VERSION ""

NS_ :

BS_:

BU_: AUDIOamp A_IVC CGW CentralPanel FCP IVI RCP RSE_L

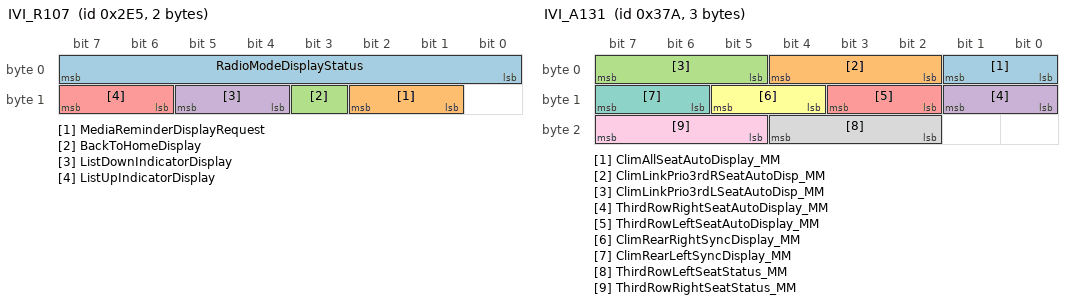
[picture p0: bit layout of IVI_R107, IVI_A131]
BO_ 741 IVI_R107: 2 IVI
  SG_ RadioModeDisplayStatus : 7|8@0+ (1,0) [0|254] "wu" CGW
  SG_ MediaReminderDisplayRequest : 10|2@0+ (1,0) [0|0] "" CGW
  SG_ BackToHomeDisplay : 11|1@0+ (1,0) [0|0] "" CGW
  SG_ ListDownIndicatorDisplay : 13|2@0+ (1,0) [0|0] "" CGW
  SG_ ListUpIndicatorDisplay : 15|2@0+ (1,0) [0|0] "" CGW

BO_ 890 IVI_A131: 3 IVI
  SG_ ClimAllSeatAutoDisplay_MM : 1|2@0+ (1,0) [0|0] "" FCP
  SG_ ClimLinkPrio3rdRSeatAutoDisp_MM : 4|3@0+ (1,0) [0|0] "" FCP
  SG_ ClimLinkPrio3rdLSeatAutoDisp_MM : 7|3@0+ (1,0) [0|0] "" FCP
  SG_ ThirdRowRightSeatAutoDisplay_MM : 9|2@0+ (1,0) [0|0] "" FCP,RCP
  SG_ ThirdRowLeftSeatAutoDisplay_MM : 11|2@0+ (1,0) [0|0] "" FCP,RCP
  SG_ ClimRearRightSyncDisplay_MM : 13|2@0+ (1,0) [0|0] "" FCP,RCP
  SG_ ClimRearLeftSyncDisplay_MM : 15|2@0+ (1,0) [0|0] "" FCP,RCP
  SG_ ThirdRowLeftSeatStatus_MM : 20|3@0+ (1,0) [0|0] "" FCP,RCP
  SG_ ThirdRowRightSeatStatus_MM : 23|3@0+ (1,0) [0|0] "" FCP,RCP

BO_ 920 OSP_Info: 8 IVI
  SG_ NavigationAlertDisplayRequest : 7|3@0+ (1,0) [0|0] "" CGW

BO_ 945 CentralPanel_R101: 2 CentralPanel
  SG_ CentralPanelMMSwitch : 6|3@0+ (1,0) [0|0] "" IVI
  SG_ CPdisplayAvailability : 7|1@0+ (1,0) [0|0] "" IVI

BO_ 961 IVI_A112: 8 IVI
  SG_ MMI_MultimediaState : 52|3@0+ (1,0) [0|0] "" CentralPanel

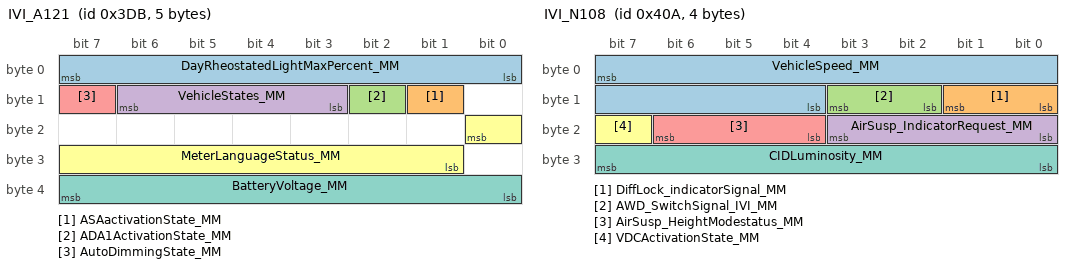
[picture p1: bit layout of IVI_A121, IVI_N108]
BO_ 987 IVI_A121: 5 IVI
  SG_ DayRheostatedLightMaxPercent_MM : 7|8@0+ (0.4,0) [0|100] "%" FCP
  SG_ ASAactivationState_MM : 9|1@0+ (1,0) [0|0] "" FCP
  SG_ ADA1ActivationState_MM : 10|1@0+ (1,0) [0|0] "" FCP
  SG_ VehicleStates_MM : 14|4@0+ (1,0) [0|0] "" CentralPanel,FCP
  SG_ AutoDimmingState_MM : 15|1@0+ (1,0) [0|0] "" CentralPanel
  SG_ MeterLanguageStatus_MM : 16|8@0+ (1,0) [0|0] "" FCP
  SG_ BatteryVoltage_MM : 39|8@0+ (0.06,6) [6|18] "V" FCP,RCP

BO_ 1026 UserSetPrefs2_MM_HS: 2 IVI
  SG_ CPdisplayDayLuminosityRequest : 6|5@0+ (5,0) [0|100] "%" CentralPanel
  SG_ CPdisplayNightLuminosityRequest : 12|5@0+ (5,0) [0|100] "%" CentralPanel

BO_ 1034 IVI_N108: 4 IVI
  SG_ VehicleSpeed_MM : 7|12@0+ (0.1,0) [0|300] "km/h" FCP
  SG_ DiffLock_indicatorSignal_MM : 9|2@0+ (1,0) [0|0] "" FCP
  SG_ AWD_SwitchSignal_IVI_MM : 11|2@0+ (1,0) [0|0] "" FCP
  SG_ AirSusp_IndicatorRequest_MM : 19|4@0+ (1,0) [0|0] "" FCP
  SG_ AirSusp_HeightModestatus_MM : 22|3@0+ (1,0) [0|0] "" FCP
  SG_ VDCActivationState_MM : 23|1@0+ (1,0) [0|0] "" FCP
  SG_ CIDLuminosity_MM : 31|8@0+ (0.4,0) [0|100] "%" CGW

BO_ 1067 HEVC_A107: 8 CGW
  SG_ RE_ElecMachineSpeed_BLMS : 42|12@0+ (10,-20000) [-20000|20000] "rpm" AUDIOamp,IVI

BO_ 1087 FCP_N101: 1 FCP
  SG_ AirSUSP_ControlPanelRequest_FCP : 2|2@0+ (1,0) [0|0] "" IVI

BO_ 1135 IVI_R104: 4 IVI
  SG_ AutoDimmingOffsetY0_MM : 7|4@0+ (1,0) [0|0] "" CentralPanel

BO_ 1158 IVI_A16: 3 IVI
  SG_ DayNightStatusForB_Switches_MM : 6|1@0+ (1,0) [0|0] "" CentralPanel
  SG_ ProbableCustomerFeedBackNeed_MM : 22|1@0+ (1,0) [0|0] "" CentralPanel

BO_ 1217 METER_A115: 8 CGW
  SG_ Uniform_Symbol_099_displayed : 1|2@0+ (1,0) [0|0] "" IVI
  SG_ Uniform_Symbol_098_displayed : 3|2@0+ (1,0) [0|0] "" IVI
  SG_ Uniform_Symbol_097_displayed : 5|2@0+ (1,0) [0|0] "" IVI
  SG_ Uniform_Symbol_096_displayed : 7|2@0+ (1,0) [0|0] "" IVI
  SG_ Uniform_Symbol_103_displayed : 9|2@0+ (1,0) [0|0] "" IVI
  SG_ Uniform_Symbol_102_displayed : 11|2@0+ (1,0) [0|0] "" IVI
  SG_ Uniform_Symbol_101_displayed : 13|2@0+ (1,0) [0|0] "" IVI
  SG_ Uniform_Symbol_100_displayed : 15|2@0+ (1,0) [0|0] "" IVI
  SG_ Uniform_Symbol_107_displayed : 17|2@0+ (1,0) [0|0] "" IVI
  SG_ Uniform_Symbol_106_displayed : 19|2@0+ (1,0) [0|0] "" IVI
  SG_ Uniform_Symbol_105_displayed : 21|2@0+ (1,0) [0|0] "" IVI
  SG_ Uniform_Symbol_104_displayed : 23|2@0+ (1,0) [0|0] "" IVI
  SG_ Uniform_Symbol_111_displayed : 25|2@0+ (1,0) [0|0] "" IVI
  SG_ Uniform_Symbol_110_displayed : 27|2@0+ (1,0) [0|0] "" IVI
  SG_ Uniform_Symbol_109_displayed : 29|2@0+ (1,0) [0|0] "" IVI
  SG_ Uniform_Symbol_108_displayed : 31|2@0+ (1,0) [0|0] "" IVI
  SG_ Uniform_Symbol_115_displayed : 33|2@0+ (1,0) [0|0] "" IVI
  SG_ Uniform_Symbol_114_displayed : 35|2@0+ (1,0) [0|0] "" IVI
  SG_ Uniform_Symbol_113_displayed : 37|2@0+ (1,0) [0|0] "" IVI
  SG_ Uniform_Symbol_112_displayed : 39|2@0+ (1,0) [0|0] "" IVI
  SG_ Uniform_Symbol_119_displayed : 41|2@0+ (1,0) [0|0] "" IVI
  SG_ Uniform_Symbol_118_displayed : 43|2@0+ (1,0) [0|0] "" IVI
  SG_ Uniform_Symbol_117_displayed : 45|2@0+ (1,0) [0|0] "" IVI
  SG_ Uniform_Symbol_116_displayed : 47|2@0+ (1,0) [0|0] "" IVI
  SG_ Uniform_Symbol_123_displayed : 49|2@0+ (1,0) [0|0] "" IVI
  SG_ Uniform_Symbol_122_displayed : 51|2@0+ (1,0) [0|0] "" IVI
  SG_ Uniform_Symbol_121_displayed : 53|2@0+ (1,0) [0|0] "" IVI
  SG_ Uniform_Symbol_120_displayed : 55|2@0+ (1,0) [0|0] "" IVI
  SG_ Uniform_Symbol_127_displayed : 57|2@0+ (1,0) [0|0] "" IVI
  SG_ Uniform_Symbol_126_displayed : 59|2@0+ (1,0) [0|0] "" IVI
  SG_ Uniform_Symbol_125_displayed : 61|2@0+ (1,0) [0|0] "" IVI
  SG_ Uniform_Symbol_124_displayed : 63|2@0+ (1,0) [0|0] "" IVI

BO_ 1222 METER_A116: 8 CGW
  SG_ Uniform_Symbol_131_displayed : 1|2@0+ (1,0) [0|0] "" IVI
  SG_ Uniform_Symbol_130_displayed : 3|2@0+ (1,0) [0|0] "" IVI
  SG_ Uniform_Symbol_129_displayed : 5|2@0+ (1,0) [0|0] "" IVI
  SG_ Uniform_Symbol_128_displayed : 7|2@0+ (1,0) [0|0] "" IVI
  SG_ Uniform_Symbol_135_displayed : 9|2@0+ (1,0) [0|0] "" IVI
  SG_ Uniform_Symbol_134_displayed : 11|2@0+ (1,0) [0|0] "" IVI
  SG_ Uniform_Symbol_133_displayed : 13|2@0+ (1,0) [0|0] "" IVI
  SG_ Uniform_Symbol_132_displayed : 15|2@0+ (1,0) [0|0] "" IVI
  SG_ Uniform_Symbol_139_displayed : 17|2@0+ (1,0) [0|0] "" IVI
  SG_ Uniform_Symbol_138_displayed : 19|2@0+ (1,0) [0|0] "" IVI
  SG_ Uniform_Symbol_137_displayed : 21|2@0+ (1,0) [0|0] "" IVI
  SG_ Uniform_Symbol_136_displayed : 23|2@0+ (1,0) [0|0] "" IVI
  SG_ Uniform_Symbol_143_displayed : 25|2@0+ (1,0) [0|0] "" IVI
  SG_ Uniform_Symbol_142_displayed : 27|2@0+ (1,0) [0|0] "" IVI
  SG_ Uniform_Symbol_141_displayed : 29|2@0+ (1,0) [0|0] "" IVI
  SG_ Uniform_Symbol_140_displayed : 31|2@0+ (1,0) [0|0] "" IVI
  SG_ Uniform_Symbol_147_displayed : 33|2@0+ (1,0) [0|0] "" IVI
  SG_ Uniform_Symbol_146_displayed : 35|2@0+ (1,0) [0|0] "" IVI
  SG_ Uniform_Symbol_145_displayed : 37|2@0+ (1,0) [0|0] "" IVI
  SG_ Uniform_Symbol_144_displayed : 39|2@0+ (1,0) [0|0] "" IVI
  SG_ Uniform_Symbol_151_displayed : 41|2@0+ (1,0) [0|0] "" IVI
  SG_ Uniform_Symbol_150_displayed : 43|2@0+ (1,0) [0|0] "" IVI
  SG_ Uniform_Symbol_149_displayed : 45|2@0+ (1,0) [0|0] "" IVI
  SG_ Uniform_Symbol_148_displayed : 47|2@0+ (1,0) [0|0] "" IVI
  SG_ Uniform_Symbol_155_displayed : 49|2@0+ (1,0) [0|0] "" IVI
  SG_ Uniform_Symbol_154_displayed : 51|2@0+ (1,0) [0|0] "" IVI
  SG_ Uniform_Symbol_153_displayed : 53|2@0+ (1,0) [0|0] "" IVI
  SG_ Uniform_Symbol_152_displayed : 55|2@0+ (1,0) [0|0] "" IVI
  SG_ Uniform_Symbol_159_displayed : 57|2@0+ (1,0) [0|0] "" IVI
  SG_ Uniform_Symbol_158_displayed : 59|2@0+ (1,0) [0|0] "" IVI
  SG_ Uniform_Symbol_157_displayed : 61|2@0+ (1,0) [0|0] "" IVI
  SG_ Uniform_Symbol_156_displayed : 63|2@0+ (1,0) [0|0] "" IVI

BO_ 1229 METER_A117: 8 CGW
  SG_ Uniform_Symbol_163_displayed : 1|2@0+ (1,0) [0|0] "" IVI
  SG_ Uniform_Symbol_162_displayed : 3|2@0+ (1,0) [0|0] "" IVI
  SG_ Uniform_Symbol_161_displayed : 5|2@0+ (1,0) [0|0] "" IVI
  SG_ Uniform_Symbol_160_displayed : 7|2@0+ (1,0) [0|0] "" IVI
  SG_ Uniform_Symbol_167_displayed : 9|2@0+ (1,0) [0|0] "" IVI
  SG_ Uniform_Symbol_166_displayed : 11|2@0+ (1,0) [0|0] "" IVI
  SG_ Uniform_Symbol_165_displayed : 13|2@0+ (1,0) [0|0] "" IVI
  SG_ Uniform_Symbol_164_displayed : 15|2@0+ (1,0) [0|0] "" IVI
  SG_ Uniform_Symbol_171_displayed : 17|2@0+ (1,0) [0|0] "" IVI
  SG_ Uniform_Symbol_170_displayed : 19|2@0+ (1,0) [0|0] "" IVI
  SG_ Uniform_Symbol_169_displayed : 21|2@0+ (1,0) [0|0] "" IVI
  SG_ Uniform_Symbol_168_displayed : 23|2@0+ (1,0) [0|0] "" IVI
  SG_ Uniform_Symbol_175_displayed : 25|2@0+ (1,0) [0|0] "" IVI
  SG_ Uniform_Symbol_174_displayed : 27|2@0+ (1,0) [0|0] "" IVI
  SG_ Uniform_Symbol_173_displayed : 29|2@0+ (1,0) [0|0] "" IVI
  SG_ Uniform_Symbol_172_displayed : 31|2@0+ (1,0) [0|0] "" IVI
  SG_ Uniform_Symbol_179_displayed : 33|2@0+ (1,0) [0|0] "" IVI
  SG_ Uniform_Symbol_178_displayed : 35|2@0+ (1,0) [0|0] "" IVI
  SG_ Uniform_Symbol_177_displayed : 37|2@0+ (1,0) [0|0] "" IVI
  SG_ Uniform_Symbol_176_displayed : 39|2@0+ (1,0) [0|0] "" IVI
  SG_ Uniform_Symbol_183_displayed : 41|2@0+ (1,0) [0|0] "" IVI
  SG_ Uniform_Symbol_182_displayed : 43|2@0+ (1,0) [0|0] "" IVI
  SG_ Uniform_Symbol_181_displayed : 45|2@0+ (1,0) [0|0] "" IVI
  SG_ Uniform_Symbol_180_displayed : 47|2@0+ (1,0) [0|0] "" IVI
  SG_ Uniform_Symbol_187_displayed : 49|2@0+ (1,0) [0|0] "" IVI
  SG_ Uniform_Symbol_186_displayed : 51|2@0+ (1,0) [0|0] "" IVI
  SG_ Uniform_Symbol_185_displayed : 53|2@0+ (1,0) [0|0] "" IVI
  SG_ Uniform_Symbol_184_displayed : 55|2@0+ (1,0) [0|0] "" IVI
  SG_ Uniform_Symbol_191_displayed : 57|2@0+ (1,0) [0|0] "" IVI
  SG_ Uniform_Symbol_190_displayed : 59|2@0+ (1,0) [0|0] "" IVI
  SG_ Uniform_Symbol_189_displayed : 61|2@0+ (1,0) [0|0] "" IVI
  SG_ Uniform_Symbol_188_displayed : 63|2@0+ (1,0) [0|0] "" IVI

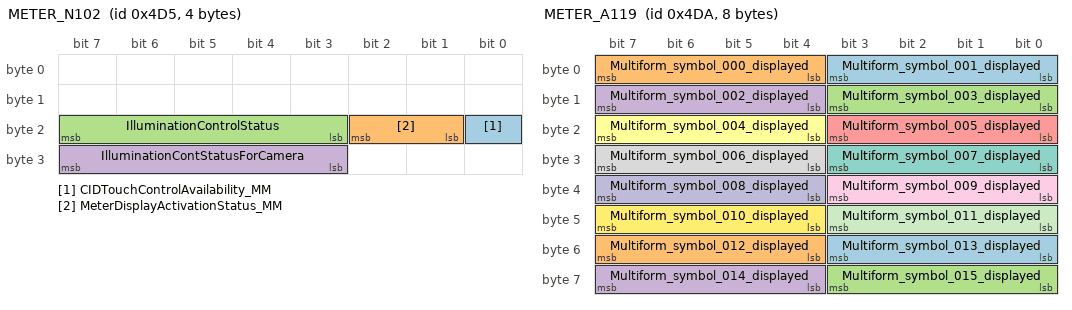
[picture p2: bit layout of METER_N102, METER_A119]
BO_ 1237 METER_N102: 4 CGW
  SG_ CIDTouchControlAvailability_MM : 16|1@0+ (1,0) [0|0] "" IVI
  SG_ MeterDisplayActivationStatus_MM : 18|2@0+ (1,0) [0|0] "" IVI
  SG_ IlluminationControlStatus : 23|5@0+ (1,0) [0|0] "" IVI
  SG_ IlluminationContStatusForCamera : 31|5@0+ (1,0) [0|0] "" IVI

BO_ 1238 METER_A118: 8 CGW
  SG_ Uniform_Symbol_195_displayed : 1|2@0+ (1,0) [0|0] "" IVI
  SG_ Uniform_Symbol_194_displayed : 3|2@0+ (1,0) [0|0] "" IVI
  SG_ Uniform_Symbol_193_displayed : 5|2@0+ (1,0) [0|0] "" IVI
  SG_ Uniform_Symbol_192_displayed : 7|2@0+ (1,0) [0|0] "" IVI
  SG_ Uniform_Symbol_199_displayed : 9|2@0+ (1,0) [0|0] "" IVI
  SG_ Uniform_Symbol_198_displayed : 11|2@0+ (1,0) [0|0] "" IVI
  SG_ Uniform_Symbol_197_displayed : 13|2@0+ (1,0) [0|0] "" IVI
  SG_ Uniform_Symbol_196_displayed : 15|2@0+ (1,0) [0|0] "" IVI
  SG_ Uniform_Symbol_203_displayed : 17|2@0+ (1,0) [0|0] "" IVI
  SG_ Uniform_Symbol_202_displayed : 19|2@0+ (1,0) [0|0] "" IVI
  SG_ Uniform_Symbol_201_displayed : 21|2@0+ (1,0) [0|0] "" IVI
  SG_ Uniform_Symbol_200_displayed : 23|2@0+ (1,0) [0|0] "" IVI
  SG_ Uniform_Symbol_207_displayed : 25|2@0+ (1,0) [0|0] "" IVI
  SG_ Uniform_Symbol_206_displayed : 27|2@0+ (1,0) [0|0] "" IVI
  SG_ Uniform_Symbol_205_displayed : 29|2@0+ (1,0) [0|0] "" IVI
  SG_ Uniform_Symbol_204_displayed : 31|2@0+ (1,0) [0|0] "" IVI
  SG_ Uniform_Symbol_211_displayed : 33|2@0+ (1,0) [0|0] "" IVI
  SG_ Uniform_Symbol_210_displayed : 35|2@0+ (1,0) [0|0] "" IVI
  SG_ Uniform_Symbol_209_displayed : 37|2@0+ (1,0) [0|0] "" IVI
  SG_ Uniform_Symbol_208_displayed : 39|2@0+ (1,0) [0|0] "" IVI
  SG_ Uniform_Symbol_215_displayed : 41|2@0+ (1,0) [0|0] "" IVI
  SG_ Uniform_Symbol_214_displayed : 43|2@0+ (1,0) [0|0] "" IVI
  SG_ Uniform_Symbol_213_displayed : 45|2@0+ (1,0) [0|0] "" IVI
  SG_ Uniform_Symbol_212_displayed : 47|2@0+ (1,0) [0|0] "" IVI
  SG_ Uniform_Symbol_219_displayed : 49|2@0+ (1,0) [0|0] "" IVI
  SG_ Uniform_Symbol_218_displayed : 51|2@0+ (1,0) [0|0] "" IVI
  SG_ Uniform_Symbol_217_displayed : 53|2@0+ (1,0) [0|0] "" IVI
  SG_ Uniform_Symbol_216_displayed : 55|2@0+ (1,0) [0|0] "" IVI
  SG_ Uniform_Symbol_223_displayed : 57|2@0+ (1,0) [0|0] "" IVI
  SG_ Uniform_Symbol_222_displayed : 59|2@0+ (1,0) [0|0] "" IVI
  SG_ Uniform_Symbol_221_displayed : 61|2@0+ (1,0) [0|0] "" IVI
  SG_ Uniform_Symbol_220_displayed : 63|2@0+ (1,0) [0|0] "" IVI

BO_ 1242 METER_A119: 8 CGW
  SG_ Multiform_symbol_001_displayed : 3|4@0+ (1,0) [0|0] "" IVI
  SG_ Multiform_symbol_000_displayed : 7|4@0+ (1,0) [0|0] "" IVI
  SG_ Multiform_symbol_003_displayed : 11|4@0+ (1,0) [0|0] "" IVI
  SG_ Multiform_symbol_002_displayed : 15|4@0+ (1,0) [0|0] "" IVI
  SG_ Multiform_symbol_005_displayed : 19|4@0+ (1,0) [0|0] "" IVI
  SG_ Multiform_symbol_004_displayed : 23|4@0+ (1,0) [0|0] "" IVI
  SG_ Multiform_symbol_007_displayed : 27|4@0+ (1,0) [0|0] "" IVI
  SG_ Multiform_symbol_006_displayed : 31|4@0+ (1,0) [0|0] "" IVI
  SG_ Multiform_symbol_009_displayed : 35|4@0+ (1,0) [0|0] "" IVI
  SG_ Multiform_symbol_008_displayed : 39|4@0+ (1,0) [0|0] "" IVI
  SG_ Multiform_symbol_011_displayed : 43|4@0+ (1,0) [0|0] "" IVI
  SG_ Multiform_symbol_010_displayed : 47|4@0+ (1,0) [0|0] "" IVI
  SG_ Multiform_symbol_013_displayed : 51|4@0+ (1,0) [0|0] "" IVI
  SG_ Multiform_symbol_012_displayed : 55|4@0+ (1,0) [0|0] "" IVI
  SG_ Multiform_symbol_015_displayed : 59|4@0+ (1,0) [0|0] "" IVI
  SG_ Multiform_symbol_014_displayed : 63|4@0+ (1,0) [0|0] "" IVI

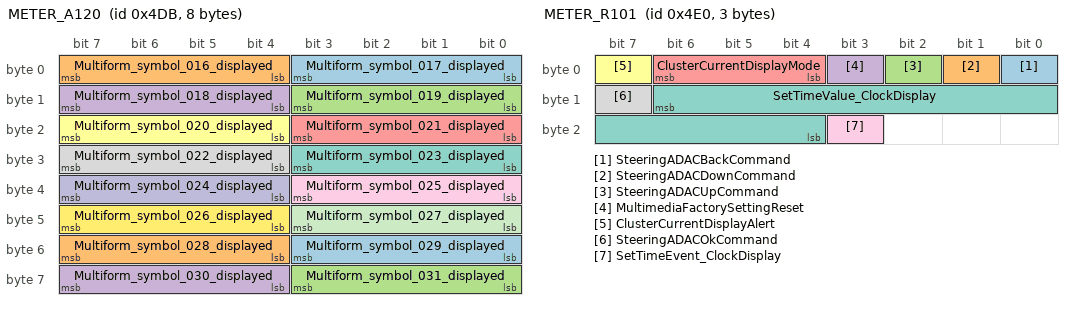
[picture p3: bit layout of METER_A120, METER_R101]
BO_ 1243 METER_A120: 8 CGW
  SG_ Multiform_symbol_017_displayed : 3|4@0+ (1,0) [0|0] "" IVI
  SG_ Multiform_symbol_016_displayed : 7|4@0+ (1,0) [0|0] "" IVI
  SG_ Multiform_symbol_019_displayed : 11|4@0+ (1,0) [0|0] "" IVI
  SG_ Multiform_symbol_018_displayed : 15|4@0+ (1,0) [0|0] "" IVI
  SG_ Multiform_symbol_021_displayed : 19|4@0+ (1,0) [0|0] "" IVI
  SG_ Multiform_symbol_020_displayed : 23|4@0+ (1,0) [0|0] "" IVI
  SG_ Multiform_symbol_023_displayed : 27|4@0+ (1,0) [0|0] "" IVI
  SG_ Multiform_symbol_022_displayed : 31|4@0+ (1,0) [0|0] "" IVI
  SG_ Multiform_symbol_025_displayed : 35|4@0+ (1,0) [0|0] "" IVI
  SG_ Multiform_symbol_024_displayed : 39|4@0+ (1,0) [0|0] "" IVI
  SG_ Multiform_symbol_027_displayed : 43|4@0+ (1,0) [0|0] "" IVI
  SG_ Multiform_symbol_026_displayed : 47|4@0+ (1,0) [0|0] "" IVI
  SG_ Multiform_symbol_029_displayed : 51|4@0+ (1,0) [0|0] "" IVI
  SG_ Multiform_symbol_028_displayed : 55|4@0+ (1,0) [0|0] "" IVI
  SG_ Multiform_symbol_031_displayed : 59|4@0+ (1,0) [0|0] "" IVI
  SG_ Multiform_symbol_030_displayed : 63|4@0+ (1,0) [0|0] "" IVI

BO_ 1248 METER_R101: 3 CGW
  SG_ SteeringADACBackCommand : 0|1@0+ (1,0) [0|0] "" IVI
  SG_ SteeringADACDownCommand : 1|1@0+ (1,0) [0|0] "" IVI
  SG_ SteeringADACUpCommand : 2|1@0+ (1,0) [0|0] "" IVI
  SG_ MultimediaFactorySettingReset : 3|1@0+ (1,0) [0|0] "" IVI
  SG_ ClusterCurrentDisplayMode : 6|3@0+ (1,0) [0|0] "" IVI
  SG_ ClusterCurrentDisplayAlert : 7|1@0+ (1,0) [0|0] "" IVI
  SG_ SetTimeValue_ClockDisplay : 14|11@0+ (1,0) [0|1440] "min" IVI
  SG_ SteeringADACOkCommand : 15|1@0+ (1,0) [0|0] "" IVI
  SG_ SetTimeEvent_ClockDisplay : 19|1@0+ (1,0) [0|0] "" IVI

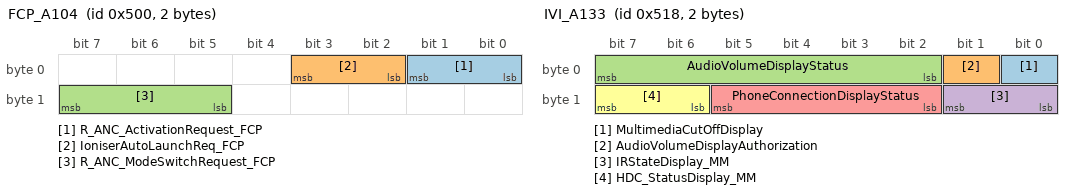
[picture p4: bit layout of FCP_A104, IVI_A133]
BO_ 1280 FCP_A104: 2 FCP
  SG_ R_ANC_ActivationRequest_FCP : 1|2@0+ (1,0) [0|0] "" IVI
  SG_ IoniserAutoLaunchReq_FCP : 3|2@0+ (1,0) [0|0] "" IVI
  SG_ R_ANC_ModeSwitchRequest_FCP : 15|3@0+ (1,0) [0|0] "" IVI

BO_ 1283 RCP_A102: 7 RCP
  SG_ RRLeftMassageActivationReq_RCP : 1|2@0+ (1,0) [0|0] "" IVI
  SG_ RRLeftLumbarMovingReq_Z_Axis_RCP : 3|2@0+ (1,0) [0|0] "" IVI
  SG_ RRLeftLumbarMovingReq_X_Axis_RCP : 5|2@0+ (1,0) [0|0] "" IVI
  SG_ RRLeftFrontHeightMovingReq_RCP : 7|2@0+ (1,0) [0|0] "" IVI
  SG_ RRLeftOttomanMovingReq_RCP : 9|2@0+ (1,0) [0|0] "" IVI
  SG_ RRLeftMassageVelocityReq_RCP : 12|3@0+ (1,0) [0|0] "" IVI
  SG_ RRLeftMassageIntensityReq_RCP : 15|3@0+ (1,0) [0|0] "" IVI
  SG_ RRLeftSlideMovingReq_RCP : 17|2@0+ (1,0) [0|0] "" IVI
  SG_ RRLeftReclinerMovingReq_RCP : 19|2@0+ (1,0) [0|0] "" IVI
  SG_ RRLeftMassageProgramReq_RCP : 23|4@0+ (1,0) [0|0] "" IVI
  SG_ RRLeftUpperbackrestMovingReq_RCP : 25|2@0+ (1,0) [0|0] "" IVI
  SG_ RRRightMassageIntensityReq_RCP : 28|3@0+ (1,0) [0|0] "" IVI
  SG_ RRRightMassageVelocityReq_RCP : 31|3@0+ (1,0) [0|0] "" IVI
  SG_ RRRightMassageActivationReq_RCP : 33|2@0+ (1,0) [0|0] "" IVI
  SG_ RRRightLumbarMovReq_Z_Axis_RCP : 35|2@0+ (1,0) [0|0] "" IVI
  SG_ RRRightLumbarMovReq_X_Axis_RCP : 37|2@0+ (1,0) [0|0] "" IVI
  SG_ RRRightFrontHeightMovingReq_RCP : 39|2@0+ (1,0) [0|0] "" IVI
  SG_ RRRightReclinerMovingReq_RCP : 41|2@0+ (1,0) [0|0] "" IVI
  SG_ RRRightOttomanMovingReq_RCP : 43|2@0+ (1,0) [0|0] "" IVI
  SG_ RRRightMassageProgramReq_RCP : 47|4@0+ (1,0) [0|0] "" IVI
  SG_ RearRightAutoReturnReq_RCP : 49|2@0+ (1,0) [0|0] "" IVI
  SG_ RearLeftAutoReturnReq_RCP : 51|2@0+ (1,0) [0|0] "" IVI
  SG_ RRRightUpperbackrestMovReq_RCP : 53|2@0+ (1,0) [0|0] "" IVI
  SG_ RRRightSlideMovingReq_RCP : 55|2@0+ (1,0) [0|0] "" IVI

BO_ 1287 IVI_A125: 8 IVI
  SG_ ClimRightTempDisplay_MM : 7|8@0+ (0.5,0) [10|127.5] "°" FCP
  SG_ ClimTempDisplay_MM : 15|8@0+ (0.5,0) [10|127.5] "°" FCP
  SG_ ClimFlowDistrDisplay_MM : 19|4@0+ (1,0) [0|0] "" FCP
  SG_ ClimBlowerLevelDisplay_MM : 23|4@0+ (1,0) [0|0] "" FCP
  SG_ ClimLinkMaxFanSpeedAutoDisp_MM : 24|3@0+ (1,0) [0|0] "" FCP
  SG_ ClimHumidSensorSensitivDisp_MM : 27|3@0+ (1,0) [0|0] "" FCP
  SG_ ClimLastFuncModiByCustomer_v2_MM : 31|4@0+ (1,0) [0|0] "" FCP
  SG_ ClimAutoDisplay_MM : 32|2@0+ (1,0) [0|0] "" FCP
  SG_ ClimACDisplay_MM : 34|2@0+ (1,0) [0|0] "" FCP
  SG_ ClimRightFlowDistrDisplay_MM : 37|3@0+ (1,0) [0|0] "" FCP
  SG_ ClimRightAutoDisplay_MM : 40|2@0+ (1,0) [0|0] "" FCP
  SG_ ClimForestDisplay_MM : 42|2@0+ (1,0) [0|0] "" FCP
  SG_ ClimDriverZoneDisplay_MM : 44|2@0+ (1,0) [0|0] "" FCP
  SG_ ClimClearnessDisplay_MM : 46|2@0+ (1,0) [0|0] "" FCP
  SG_ ClimClearnessDisplayStatus_MM : 49|1@0+ (1,0) [0|0] "" FCP
  SG_ ClimCabinTempDisplayUnit_MM : 50|1@0+ (1,0) [0|0] "" FCP,RCP
  SG_ ClimBlowingLevelDisplayStatus_MM : 51|1@0+ (1,0) [0|0] "" FCP,RCP
  SG_ ClimACDisplayStatus_MM : 52|1@0+ (1,0) [0|0] "" FCP
  SG_ ClimSyncDisplay_MM : 54|2@0+ (1,0) [0|0] "" FCP,RCP
  SG_ ClimSyncDisplayStatus_MM : 56|1@0+ (1,0) [0|0] "" FCP,RCP
  SG_ ClimRightTempDisplayStatus_MM : 57|1@0+ (1,0) [0|0] "" FCP
  SG_ ClimRightFloDistDisplayStatus_MM : 58|1@0+ (1,0) [0|0] "" FCP
  SG_ ClimOFFModeDisplayStatus_MM : 59|1@0+ (1,0) [0|0] "" FCP,RCP
  SG_ ClimOFFModeDisplay_MM : 60|1@0+ (1,0) [0|0] "" FCP
  SG_ ClimForestDisplayStatus_MM : 61|1@0+ (1,0) [0|0] "" FCP
  SG_ ClimFlowDistrDisplayStatus_MM : 62|1@0+ (1,0) [0|0] "" FCP,RCP
  SG_ ClimDriverZoneDisplayStatus_MM : 63|1@0+ (1,0) [0|0] "" FCP

BO_ 1288 IVI_A126: 8 IVI
  SG_ ClimRearLeftTempDisplay_MM : 7|8@0+ (0.5,10) [10|127.5] "°" FCP,RCP
  SG_ ClimRearRightTempDisplay_MM : 15|8@0+ (0.5,0) [10|127.5] "°" FCP,RCP
  SG_ ClimRearRightBlowLevelDisplay_MM : 19|4@0+ (1,0) [0|0] "" FCP,RCP
  SG_ ClimRearLeftBlowLevelDisplay_MM : 23|4@0+ (1,0) [0|0] "" FCP,RCP
  SG_ ClimRearLeftFlowDistrDisplay_MM : 25|3@0+ (1,0) [0|0] "" FCP,RCP
  SG_ ClimLinkPriorHeatStrgAutoDisp_MM : 28|3@0+ (1,0) [0|0] "" FCP
  SG_ ClimLinkPrioRearSeatsAutoDisp_MM : 31|3@0+ (1,0) [0|0] "" FCP
  SG_ SecondRowLeftSeatStatus_MM : 32|3@0+ (1,0) [0|0] "" FCP,RCP
  SG_ ClimVariableAirFlowDisplay_MM : 35|3@0+ (1,0) [0|0] "" FCP
  SG_ ClimRearRightFlowDistrDisplay_MM : 38|3@0+ (1,0) [0|0] "" FCP,RCP
  SG_ ClimRearLockStatus_MM : 40|2@0+ (1,0) [0|0] "" FCP,RCP
  SG_ ClimRearLeftAutoDisplay_MM : 42|2@0+ (1,0) [0|0] "" FCP,RCP
  SG_ SecondRowRightSeatStatus_MM : 45|3@0+ (1,0) [0|0] "" FCP,RCP
  SG_ ClimHeatedSteerWheelDispStatu_MM : 48|1@0+ (1,0) [0|0] "" FCP
  SG_ RearSeatsLockStatus_MM : 50|2@0+ (1,0) [0|0] "" FCP
  SG_ SecondRowRightSeatAutoDisplay_MM : 52|2@0+ (1,0) [0|0] "" FCP,RCP
  SG_ SecondRowLeftSeatAutoDisplay_MM : 54|2@0+ (1,0) [0|0] "" FCP,RCP
  SG_ SecondRowRightSeatDispStatus_MM : 56|1@0+ (1,0) [0|0] "" FCP,RCP
  SG_ SecondRowLeftSeatDispStatus_MM : 57|1@0+ (1,0) [0|0] "" FCP,RCP
  SG_ ClimTempDisplayStatus_MM : 58|1@0+ (1,0) [0|0] "" FCP
  SG_ ClimRearRightTempDispStatus_MM : 59|1@0+ (1,0) [0|0] "" FCP,RCP
  SG_ ClimRearRightFloDistDispStatu_MM : 60|1@0+ (1,0) [0|0] "" FCP,RCP
  SG_ ClimRearOFFModeDisplay_MM : 61|1@0+ (1,0) [0|0] "" FCP,RCP
  SG_ ClimRearLeftTempDisplayStatus_MM : 62|1@0+ (1,0) [0|0] "" FCP,RCP
  SG_ ClimRearLeftFlowDistDispStatu_MM : 63|1@0+ (1,0) [0|0] "" FCP,RCP

BO_ 1289 IVI_A127: 8 IVI
  SG_ RRRightMassageProgramState_MM : 3|4@0+ (1,0) [0|0] "" RCP
  SG_ RRLeftMassageProgramState_MM : 7|4@0+ (1,0) [0|0] "" RCP
  SG_ ClimLinkPrioritFLSeatAutoDisp_MM : 9|3@0+ (1,0) [0|0] "" FCP
  SG_ ClimAQSSensitivityDisplay_MM : 15|3@0+ (1,0) [0|0] "" FCP
  SG_ RRLeftMassageIntensityState_MM : 16|3@0+ (1,0) [0|0] "" RCP
  SG_ FrontRightSeatStatus_MM : 19|3@0+ (1,0) [0|0] "" FCP
  SG_ FrontLeftSeatStatus_MM : 22|3@0+ (1,0) [0|0] "" FCP
  SG_ RRLeftMassageVelocityState_MM : 26|3@0+ (1,0) [0|0] "" RCP
  SG_ RRRightMassageIntensityState_MM : 29|3@0+ (1,0) [0|0] "" RCP
  SG_ ClimForcedRecyDisplay_MM : 32|2@0+ (1,0) [0|0] "" FCP
  SG_ ClimForcedFreshDisplay_MM : 34|2@0+ (1,0) [0|0] "" FCP
  SG_ ClimAutoRecyclingDisplay_MM : 36|2@0+ (1,0) [0|0] "" FCP
  SG_ RRRightMassageVelocityState_MM : 39|3@0+ (1,0) [0|0] "" RCP
  SG_ FrontRightSeatAutoDisplay_MM : 40|2@0+ (1,0) [0|0] "" FCP
  SG_ FrontLeftSeatAutoDisplay_MM : 42|2@0+ (1,0) [0|0] "" FCP
  SG_ ClimRearDefrostDisplay_MM : 44|2@0+ (1,0) [0|0] "" FCP
  SG_ ClimFrontDefrostDisplay_MM : 46|2@0+ (1,0) [0|0] "" FCP
  SG_ ClimRearDefrostDisplayStatus_MM : 48|1@0+ (1,0) [0|0] "" FCP
  SG_ ClimFrontDefrostDisplayStatus_MM : 49|1@0+ (1,0) [0|0] "" FCP
  SG_ ClimForcedRecyDisplayStatus_MM : 50|1@0+ (1,0) [0|0] "" FCP
  SG_ ClimForcedFreshDisplayStatus_MM : 51|1@0+ (1,0) [0|0] "" FCP
  SG_ ClimAutoRecyDisplayStatus_MM : 52|1@0+ (1,0) [0|0] "" FCP
  SG_ IoniserAutoLaunchState_MM : 54|2@0+ (1,0) [0|0] "" FCP
  SG_ FrontRightSeatDisplayStatus_MM : 62|1@0+ (1,0) [0|0] "" FCP
  SG_ FrontLeftSeatDisplayStatus_MM : 63|1@0+ (1,0) [0|0] "" FCP

BO_ 1297 IVI_A128: 8 IVI
  SG_ PowerTrainSettingState_MM : 2|4@0+ (1,0) [0|0] "" FCP
  SG_ DriveModeState_MM : 7|5@0+ (1,0) [0|0] "" FCP
  SG_ VDCSettingState_MM : 10|4@0+ (1,0) [0|0] "" FCP
  SG_ SteeringSettingState_MM : 14|4@0+ (1,0) [0|0] "" FCP
  SG_ R_ANC_ModeStatus_MM : 16|3@0+ (1,0) [0|0] "" FCP
  SG_ CurrentUserState_v2_MM : 19|3@0+ (1,0) [0|0] "" FCP
  SG_ AWDSettingState_MM : 22|3@0+ (1,0) [0|0] "" FCP
  SG_ UserSettingCopySource_MM : 26|3@0+ (1,0) [0|0] "" FCP
  SG_ SuspensionSettingState_MM : 29|3@0+ (1,0) [0|0] "" FCP
  SG_ RRsunshadeRequest_MM : 32|2@0+ (1,0) [0|0] "" RCP
  SG_ R_ANC_ActivationStatus_MM : 34|2@0+ (1,0) [0|0] "" FCP
  SG_ ClimHeatedSteeringWheelDisp_MM : 36|2@0+ (1,0) [0|0] "" FCP
  SG_ UserSettingCopyTarget_MM : 39|3@0+ (1,0) [0|0] "" FCP
  SG_ User3_RegistrationState_MM : 40|1@0+ (1,0) [0|0] "" FCP
  SG_ User2_RegistrationState_MM : 41|1@0+ (1,0) [0|0] "" FCP
  SG_ User1_RegistrationState_MM : 42|1@0+ (1,0) [0|0] "" FCP
  SG_ RRRightMassageActivationState_MM : 43|1@0+ (1,0) [0|0] "" RCP
  SG_ RRLeftMassageActivationState_MM : 44|1@0+ (1,0) [0|0] "" RCP
  SG_ RearRightAutoReturnState_MM : 45|1@0+ (1,0) [0|0] "" RCP
  SG_ RearLeftAutoReturnState_MM : 46|1@0+ (1,0) [0|0] "" RCP
  SG_ ClimHeatedStrgWheelAutoDisp_MM : 49|2@0+ (1,0) [0|0] "" FCP
  SG_ ClimLinkPrioritFRSeatAutoDisp_MM : 52|3@0+ (1,0) [0|0] "" FCP
  SG_ UserSettingCopyRequest_MM : 53|1@0+ (1,0) [0|0] "" FCP
  SG_ User5_RegistrationState_MM : 54|1@0+ (1,0) [0|0] "" FCP
  SG_ User4_RegistrationState_MM : 55|1@0+ (1,0) [0|0] "" FCP
  SG_ ClimRightBlowingLevelDisplay_MM : 60|4@0+ (1,0) [0|0] "" FCP
  SG_ ClimLinkPrioritRRSeatAutoDisp_MM : 63|3@0+ (1,0) [0|0] "" FCP

BO_ 1304 IVI_A133: 2 IVI
  SG_ MultimediaCutOffDisplay : 0|1@0+ (1,0) [0|0] "" CGW
  SG_ AudioVolumeDisplayAuthorization : 1|1@0+ (1,0) [0|0] "" CGW
  SG_ AudioVolumeDisplayStatus : 7|6@0+ (1,0) [0|40] "wu" CGW
  SG_ IRStateDisplay_MM : 9|2@0+ (1,0) [0|0] "" FCP
  SG_ PhoneConnectionDisplayStatus : 13|4@0+ (1,0) [0|0] "" CGW
  SG_ HDC_StatusDisplay_MM : 15|2@0+ (1,0) [0|0] "" FCP

BO_ 1309 RCP_A101: 8 RCP
  SG_ ClimFPrearRightBlowRequest_RCP : 3|4@0+ (1,0) [0|0] "" IVI
  SG_ ClimFPRearLeftBlowingRequest_RCP : 7|4@0+ (1,0) [0|0] "" IVI
  SG_ ClimRearRightFlowDisFeetPush_RCP : 10|1@0+ (1,0) [0|1] "" IVI
  SG_ ClimRearModeOFFPush_RCP : 11|1@0+ (1,0) [0|1] "-" IVI
  SG_ ClimRearRightFlowDisVentPush_RCP : 12|1@0+ (1,0) [0|1] "" IVI
  SG_ ClimRearLeftFlowDistFeetPush_RCP : 13|1@0+ (1,0) [0|1] "" IVI
  SG_ ClimRearLeftFlowDistVentPush_RCP : 14|1@0+ (1,0) [0|1] "" IVI
  SG_ ClimRearLeftAutoNormalPush_RCP : 15|1@0+ (1,0) [0|1] "-" IVI
  SG_ ClimRearLeftTempRequest_RCP : 23|8@0+ (0.5,10) [10|127.5] "°" IVI
  SG_ ClimRearRightTempRequest_RCP : 31|8@0+ (0.5,10) [10|127.5] "°" IVI
  SG_ SecondRowRightSeatAutoReq_RCP : 33|2@0+ (1,0) [0|0] "" IVI
  SG_ SecondRowLeftSeatRequest_RCP : 37|4@0+ (1,0) [0|0] "" IVI
  SG_ SecondRowLeftSeatAutoRequest_RCP : 39|2@0+ (1,0) [0|0] "" IVI
  SG_ RRsunshade_Movement : 43|3@0+ (1,0) [0|0] "" IVI
  SG_ SecondRowRightSeatRequest_RCP : 47|4@0+ (1,0) [0|0] "" IVI
  SG_ ThirdRowLeftSeatRequest_RCP : 50|3@0+ (1,0) [0|0] "" IVI
  SG_ ClimRearRightAutoNormalPush_RCP : 51|1@0+ (1,0) [0|1] "-" IVI
  SG_ ClimRearRightSyncPush_RCP : 52|1@0+ (1,0) [0|1] "-" IVI
  SG_ ClimRearLeftSyncPush_RCP : 53|1@0+ (1,0) [0|1] "-" IVI
  SG_ RRsunshade_Position : 55|2@0+ (1,0) [0|0] "" IVI
  SG_ ThirdRowRightSeatAutoRequest_RCP : 58|2@0+ (1,0) [0|0] "" IVI
  SG_ ThirdRowLeftSeatAutoRequest_RCP : 60|2@0+ (1,0) [0|0] "" IVI
  SG_ ThirdRowRightSeatRequest_RCP : 63|3@0+ (1,0) [0|0] "" IVI

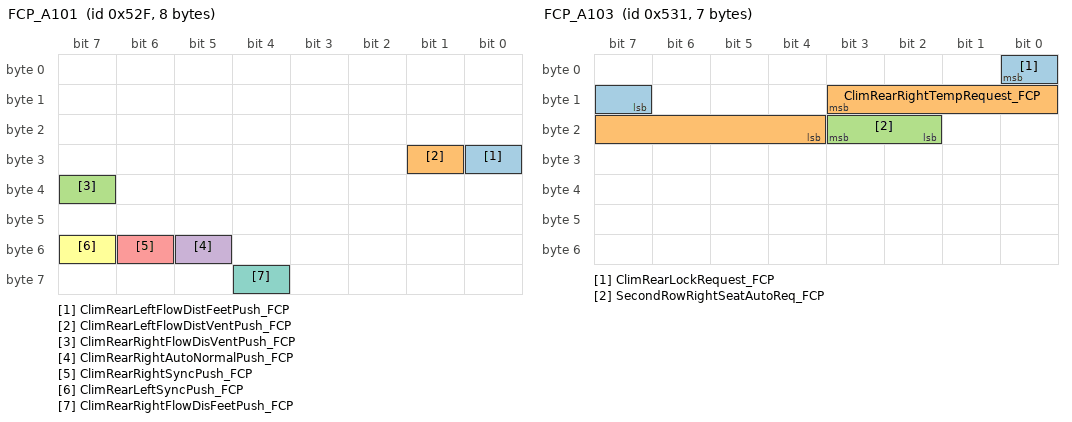
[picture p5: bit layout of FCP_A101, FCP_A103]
BO_ 1327 FCP_A101: 8 FCP
  SG_ ClimRearLeftFlowDistFeetPush_FCP : 24|1@0+ (1,0) [0|1] "" IVI
  SG_ ClimRearLeftFlowDistVentPush_FCP : 25|1@0+ (1,0) [0|1] "" IVI
  SG_ ClimRearRightFlowDisVentPush_FCP : 39|1@0+ (1,0) [0|1] "" IVI
  SG_ ClimRearRightAutoNormalPush_FCP : 53|1@0+ (1,0) [0|1] "-" IVI
  SG_ ClimRearRightSyncPush_FCP : 54|1@0+ (1,0) [0|1] "-" IVI
  SG_ ClimRearLeftSyncPush_FCP : 55|1@0+ (1,0) [0|1] "-" IVI
  SG_ ClimRearRightFlowDisFeetPush_FCP : 60|1@0+ (1,0) [0|1] "" IVI

BO_ 1329 FCP_A103: 7 FCP
  SG_ ClimRearLockRequest_FCP : 0|2@0+ (1,0) [0|0] "" IVI
  SG_ ClimRearRightTempRequest_FCP : 11|8@0+ (0.5,10) [10|127.5] "°" IVI
  SG_ SecondRowRightSeatAutoReq_FCP : 19|2@0+ (1,0) [0|0] "" IVI

BO_ 1368 GW_MMI_Info1_HS: 2 IVI
  SG_ DayNightStatus_MM : 5|2@0+ (1,0) [0|0] "" CentralPanel,FCP,RCP
  SG_ DimmingValue : 15|8@0+ (0.4,0) [0|100] "%" CentralPanel,FCP

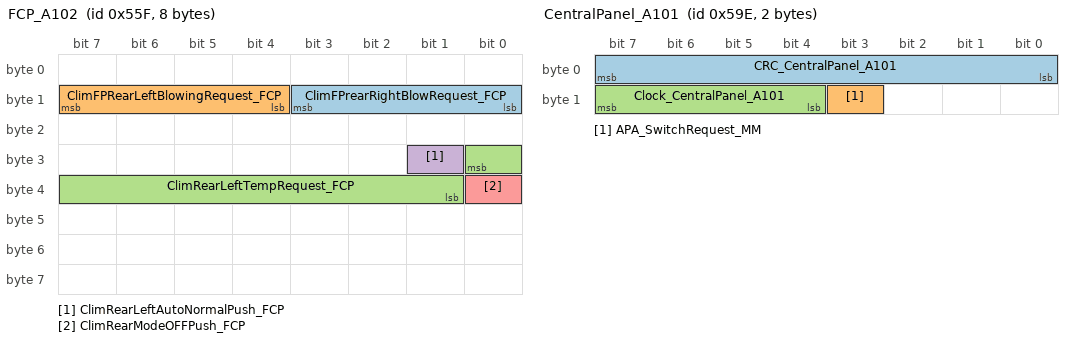
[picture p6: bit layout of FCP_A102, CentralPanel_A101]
BO_ 1375 FCP_A102: 8 FCP
  SG_ ClimFPrearRightBlowRequest_FCP : 11|4@0+ (1,0) [0|0] "" IVI
  SG_ ClimFPRearLeftBlowingRequest_FCP : 15|4@0+ (1,0) [0|0] "" IVI
  SG_ ClimRearLeftTempRequest_FCP : 24|8@0+ (0.5,10) [10|127.5] "°" IVI
  SG_ ClimRearLeftAutoNormalPush_FCP : 25|1@0+ (1,0) [0|1] "-" IVI
  SG_ ClimRearModeOFFPush_FCP : 32|1@0+ (1,0) [0|1] "-" IVI

BO_ 1400 GW_DiagInfo: 5 IVI
  SG_ GADE_MM_v2 : 37|3@0+ (1,0) [0|0] "" CentralPanel,FCP,RCP

BO_ 1415 IVI_R101: 5 IVI
  SG_ DisplayActivation : 7|1@0+ (1,0) [0|0] "" CentralPanel

BO_ 1423 GW_SEND_WakeUpInfo: 4 IVI
  SG_ MM_WakeUpSleepCommand : 31|2@0+ (1,0) [0|0] "" A_IVC,CGW

BO_ 1433 METER_R103: 4 CGW
  SG_ Current_Alert_ID_displayed : 7|32@0+ (1,0) [0|0] "" IVI

BO_ 1438 CentralPanel_A101: 2 CentralPanel
  SG_ CRC_CentralPanel_A101 : 7|8@0+ (1,0) [0|255] "" IVI
  SG_ APA_SwitchRequest_MM : 11|1@0+ (1,0) [0|0] "" IVI
  SG_ Clock_CentralPanel_A101 : 15|4@0+ (1,0) [0|15] "" IVI

BO_ 1445 METER_A112: 8 CGW
  SG_ Uniform_Symbol_003_displayed : 1|2@0+ (1,0) [0|0] "" IVI
  SG_ Uniform_Symbol_002_displayed : 3|2@0+ (1,0) [0|0] "" IVI
  SG_ Uniform_Symbol_001_displayed : 5|2@0+ (1,0) [0|0] "" IVI
  SG_ Uniform_Symbol_000_displayed : 7|2@0+ (1,0) [0|0] "" IVI
  SG_ Uniform_Symbol_007_displayed : 9|2@0+ (1,0) [0|0] "" IVI
  SG_ Uniform_Symbol_006_displayed : 11|2@0+ (1,0) [0|0] "" IVI
  SG_ Uniform_Symbol_005_displayed : 13|2@0+ (1,0) [0|0] "" IVI
  SG_ Uniform_Symbol_004_displayed : 15|2@0+ (1,0) [0|0] "" IVI
  SG_ Uniform_Symbol_011_displayed : 17|2@0+ (1,0) [0|0] "" IVI
  SG_ Uniform_Symbol_010_displayed : 19|2@0+ (1,0) [0|0] "" IVI
  SG_ Uniform_Symbol_009_displayed : 21|2@0+ (1,0) [0|0] "" IVI
  SG_ Uniform_Symbol_008_displayed : 23|2@0+ (1,0) [0|0] "" IVI
  SG_ Uniform_Symbol_015_displayed : 25|2@0+ (1,0) [0|0] "" IVI
  SG_ Uniform_Symbol_014_displayed : 27|2@0+ (1,0) [0|0] "" IVI
  SG_ Uniform_Symbol_013_displayed : 29|2@0+ (1,0) [0|0] "" IVI
  SG_ Uniform_Symbol_012_displayed : 31|2@0+ (1,0) [0|0] "" IVI
  SG_ Uniform_Symbol_019_displayed : 33|2@0+ (1,0) [0|0] "" IVI
  SG_ Uniform_Symbol_018_displayed : 35|2@0+ (1,0) [0|0] "" IVI
  SG_ Uniform_Symbol_017_displayed : 37|2@0+ (1,0) [0|0] "" IVI
  SG_ Uniform_Symbol_016_displayed : 39|2@0+ (1,0) [0|0] "" IVI
  SG_ Uniform_Symbol_023_displayed : 41|2@0+ (1,0) [0|0] "" IVI
  SG_ Uniform_Symbol_022_displayed : 43|2@0+ (1,0) [0|0] "" IVI
  SG_ Uniform_Symbol_021_displayed : 45|2@0+ (1,0) [0|0] "" IVI
  SG_ Uniform_Symbol_020_displayed : 47|2@0+ (1,0) [0|0] "" IVI
  SG_ Uniform_Symbol_027_displayed : 49|2@0+ (1,0) [0|0] "" IVI
  SG_ Uniform_Symbol_026_displayed : 51|2@0+ (1,0) [0|0] "" IVI
  SG_ Uniform_Symbol_025_displayed : 53|2@0+ (1,0) [0|0] "" IVI
  SG_ Uniform_Symbol_024_displayed : 55|2@0+ (1,0) [0|0] "" IVI
  SG_ Uniform_Symbol_031_displayed : 57|2@0+ (1,0) [0|0] "" IVI
  SG_ Uniform_Symbol_030_displayed : 59|2@0+ (1,0) [0|0] "" IVI
  SG_ Uniform_Symbol_029_displayed : 61|2@0+ (1,0) [0|0] "" IVI
  SG_ Uniform_Symbol_028_displayed : 63|2@0+ (1,0) [0|0] "" IVI

BO_ 1467 IVI_A113: 3 IVI
  SG_ DistanceTotalizer_MM : 7|22@0+ (1,0) [0|2600000] "km" CentralPanel,FCP,RCP

BO_ 1493 HEVC_A150: 8 CGW
  SG_ RE_ElecMachineTorque_BLMS : 37|11@0+ (0.5,-300) [-300|500] "Nm" AUDIOamp,IVI

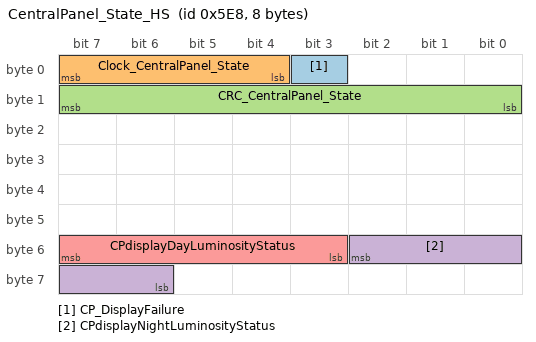
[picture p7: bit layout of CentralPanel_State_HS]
BO_ 1512 CentralPanel_State_HS: 8 CentralPanel
  SG_ CP_DisplayFailure : 3|1@0+ (1,0) [0|0] "" IVI
  SG_ Clock_CentralPanel_State : 7|4@0+ (1,0) [0|15] "" IVI
  SG_ CRC_CentralPanel_State : 15|8@0+ (1,0) [0|255] "" IVI
  SG_ CPdisplayNightLuminosityStatus : 50|5@0+ (5,0) [0|100] "%" IVI
  SG_ CPdisplayDayLuminosityStatus : 55|5@0+ (5,0) [0|100] "%" IVI

BO_ 1515 METER_A114: 8 CGW
  SG_ Uniform_Symbol_067_displayed : 1|2@0+ (1,0) [0|0] "" IVI
  SG_ Uniform_Symbol_066_displayed : 3|2@0+ (1,0) [0|0] "" IVI
  SG_ Uniform_Symbol_065_displayed : 5|2@0+ (1,0) [0|0] "" IVI
  SG_ Uniform_Symbol_064_displayed : 7|2@0+ (1,0) [0|0] "" IVI
  SG_ Uniform_Symbol_071_displayed : 9|2@0+ (1,0) [0|0] "" IVI
  SG_ Uniform_Symbol_070_displayed : 11|2@0+ (1,0) [0|0] "" IVI
  SG_ Uniform_Symbol_069_displayed : 13|2@0+ (1,0) [0|0] "" IVI
  SG_ Uniform_Symbol_068_displayed : 15|2@0+ (1,0) [0|0] "" IVI
  SG_ Uniform_Symbol_075_displayed : 17|2@0+ (1,0) [0|0] "" IVI
  SG_ Uniform_Symbol_074_displayed : 19|2@0+ (1,0) [0|0] "" IVI
  SG_ Uniform_Symbol_073_displayed : 21|2@0+ (1,0) [0|0] "" IVI
  SG_ Uniform_Symbol_072_displayed : 23|2@0+ (1,0) [0|0] "" IVI
  SG_ Uniform_Symbol_079_displayed : 25|2@0+ (1,0) [0|0] "" IVI
  SG_ Uniform_Symbol_078_displayed : 27|2@0+ (1,0) [0|0] "" IVI
  SG_ Uniform_Symbol_077_displayed : 29|2@0+ (1,0) [0|0] "" IVI
  SG_ Uniform_Symbol_076_displayed : 31|2@0+ (1,0) [0|0] "" IVI
  SG_ Uniform_Symbol_083_displayed : 33|2@0+ (1,0) [0|0] "" IVI
  SG_ Uniform_Symbol_082_displayed : 35|2@0+ (1,0) [0|0] "" IVI
  SG_ Uniform_Symbol_081_displayed : 37|2@0+ (1,0) [0|0] "" IVI
  SG_ Uniform_Symbol_080_displayed : 39|2@0+ (1,0) [0|0] "" IVI
  SG_ Uniform_Symbol_087_displayed : 41|2@0+ (1,0) [0|0] "" IVI
  SG_ Uniform_Symbol_086_displayed : 43|2@0+ (1,0) [0|0] "" IVI
  SG_ Uniform_Symbol_085_displayed : 45|2@0+ (1,0) [0|0] "" IVI
  SG_ Uniform_Symbol_084_displayed : 47|2@0+ (1,0) [0|0] "" IVI
  SG_ Uniform_Symbol_091_displayed : 49|2@0+ (1,0) [0|0] "" IVI
  SG_ Uniform_Symbol_090_displayed : 51|2@0+ (1,0) [0|0] "" IVI
  SG_ Uniform_Symbol_089_displayed : 53|2@0+ (1,0) [0|0] "" IVI
  SG_ Uniform_Symbol_088_displayed : 55|2@0+ (1,0) [0|0] "" IVI
  SG_ Uniform_Symbol_095_displayed : 57|2@0+ (1,0) [0|0] "" IVI
  SG_ Uniform_Symbol_094_displayed : 59|2@0+ (1,0) [0|0] "" IVI
  SG_ Uniform_Symbol_093_displayed : 61|2@0+ (1,0) [0|0] "" IVI
  SG_ Uniform_Symbol_092_displayed : 63|2@0+ (1,0) [0|0] "" IVI

BO_ 1519 IVI_A101: 8 IVI
  SG_ KeyLinkInitializationState : 10|1@0+ (1,0) [0|0] "" FCP
  SG_ KeyLinkActivationState : 11|1@0+ (1,0) [0|0] "" FCP

BO_ 1525 METER_A113: 8 CGW
  SG_ Uniform_Symbol_035_displayed : 1|2@0+ (1,0) [0|0] "" IVI
  SG_ Uniform_Symbol_034_displayed : 3|2@0+ (1,0) [0|0] "" IVI
  SG_ Uniform_Symbol_033_displayed : 5|2@0+ (1,0) [0|0] "" IVI
  SG_ Uniform_Symbol_032_displayed : 7|2@0+ (1,0) [0|0] "" IVI
  SG_ Uniform_Symbol_039_displayed : 9|2@0+ (1,0) [0|0] "" IVI
  SG_ Uniform_Symbol_038_displayed : 11|2@0+ (1,0) [0|0] "" IVI
  SG_ Uniform_Symbol_037_displayed : 13|2@0+ (1,0) [0|0] "" IVI
  SG_ Uniform_Symbol_036_displayed : 15|2@0+ (1,0) [0|0] "" IVI
  SG_ Uniform_Symbol_043_displayed : 17|2@0+ (1,0) [0|0] "" IVI
  SG_ Uniform_Symbol_042_displayed : 19|2@0+ (1,0) [0|0] "" IVI
  SG_ Uniform_Symbol_041_displayed : 21|2@0+ (1,0) [0|0] "" IVI
  SG_ Uniform_Symbol_040_displayed : 23|2@0+ (1,0) [0|0] "" IVI
  SG_ Uniform_Symbol_047_displayed : 25|2@0+ (1,0) [0|0] "" IVI
  SG_ Uniform_Symbol_046_displayed : 27|2@0+ (1,0) [0|0] "" IVI
  SG_ Uniform_Symbol_045_displayed : 29|2@0+ (1,0) [0|0] "" IVI
  SG_ Uniform_Symbol_044_displayed : 31|2@0+ (1,0) [0|0] "" IVI
  SG_ Uniform_Symbol_051_displayed : 33|2@0+ (1,0) [0|0] "" IVI
  SG_ Uniform_Symbol_050_displayed : 35|2@0+ (1,0) [0|0] "" IVI
  SG_ Uniform_Symbol_049_displayed : 37|2@0+ (1,0) [0|0] "" IVI
  SG_ Uniform_Symbol_048_displayed : 39|2@0+ (1,0) [0|0] "" IVI
  SG_ Uniform_Symbol_055_displayed : 41|2@0+ (1,0) [0|0] "" IVI
  SG_ Uniform_Symbol_054_displayed : 43|2@0+ (1,0) [0|0] "" IVI
  SG_ Uniform_Symbol_053_displayed : 45|2@0+ (1,0) [0|0] "" IVI
  SG_ Uniform_Symbol_052_displayed : 47|2@0+ (1,0) [0|0] "" IVI
  SG_ Uniform_Symbol_059_displayed : 49|2@0+ (1,0) [0|0] "" IVI
  SG_ Uniform_Symbol_058_displayed : 51|2@0+ (1,0) [0|0] "" IVI
  SG_ Uniform_Symbol_057_displayed : 53|2@0+ (1,0) [0|0] "" IVI
  SG_ Uniform_Symbol_056_displayed : 55|2@0+ (1,0) [0|0] "" IVI
  SG_ Uniform_Symbol_063_displayed : 57|2@0+ (1,0) [0|0] "" IVI
  SG_ Uniform_Symbol_062_displayed : 59|2@0+ (1,0) [0|0] "" IVI
  SG_ Uniform_Symbol_061_displayed : 61|2@0+ (1,0) [0|0] "" IVI
  SG_ Uniform_Symbol_060_displayed : 63|2@0+ (1,0) [0|0] "" IVI

BO_ 1542 RADIO_to_AMPLI: 8 IVI
  SG_ RADIO_to_AMPLI : 7|64@0+ (1,0) [0|0] "" AUDIOamp

BO_ 1576 RADIO_to_CLUSTER: 8 IVI
  SG_ RADIO_to_CLUSTER : 7|64@0+ (1,0) [0|0] "" CGW

BO_ 1617 RADIO_to_METER2: 8 IVI
  SG_ RADIO_to_METER2 : 7|64@0+ (1,0) [0|0] "" CGW

BO_ 1661 IVI_N104: 8 IVI
  SG_ VDCDeactivationDisplayRequest_MM : 48|1@0+ (1,0) [0|0] "" FCP

BO_ 1670 AMPLI_to_RADIO: 8 AUDIOamp
  SG_ AMPLI_to_RADIO : 7|64@0+ (1,0) [0|0] "" IVI

BO_ 1704 CLUSTER_to_RADIO: 8 CGW
  SG_ CLUSTER_to_RADIO : 7|64@0+ (1,0) [0|0] "" IVI

BO_ 1745 METER2_to_RADIO: 8 CGW
  SG_ METER2_to_RADIO : 7|64@0+ (1,0) [0|0] "" IVI

BO_ 1812 DTOOL_to_CPANEL: 8 IVI
  SG_ DTOOL_to_CPANEL : 7|64@0+ (1,0) [0|0] "" CentralPanel

BO_ 1844 CPANEL_to_DTOOL: 8 CentralPanel
  SG_ CPANEL_to_DTOOL : 7|64@0+ (1,0) [0|0] "" IVI

BO_ 2564460018 DTOOL_to_FCP: 8 IVI
  SG_ DTOOL_to_FCP : 7|64@0+ (1,0) [0|0] "" FCP

BO_ 2564460274 DTOOL_to_RCP: 8 IVI
  SG_ DTOOL_to_RCP : 7|64@0+ (1,0) [0|0] "" RCP

BO_ 2564485773 FCP_to_DTOOL: 8 FCP
  SG_ FCP_to_DTOOL : 7|64@0+ (1,0) [0|0] "" IVI

BO_ 2564485774 RCP_to_DTOOL: 8 RCP
  SG_ RCP_to_DTOOL : 7|64@0+ (1,0) [0|0] "" IVI

BO_ 2609102854 IVI_WakeUpFrame_extd: 2 IVI
  SG_ IVI_WakeUp_Signal : 7|16@0+ (1,0) [0|0] "" A_IVC

VAL_ 741 MediaReminderDisplayRequest 0 "No display" 1 "Audio reminder display" 2 "Phone reminder display" 3 "Not Used";
VAL_ 741 BackToHomeDisplay 0 "No request" 1 "Back to Home request";
VAL_ 741 ListDownIndicatorDisplay 0 "No display" 1 "Down display" 2 "End of list display" 3 "Not Used";
VAL_ 741 ListUpIndicatorDisplay 0 "No display" 1 "Up display" 2 "End of list display" 3 "Not Used";
VAL_ 890 ClimAllSeatAutoDisplay_MM 0 "No display" 1 "Auto activated" 2 "Auto not activated" 3 "Not Used";
VAL_ 890 ClimLinkPrio3rdRSeatAutoDisp_MM 0 "No display" 1 "Level 1" 2 "Level 2" 3 "Level 3" 4 "Level 4" 5 "Level 5" 6 "OFF" 7 "Not Used";
VAL_ 890 ClimLinkPrio3rdLSeatAutoDisp_MM 0 "No display" 1 "Level 1" 2 "Level 2" 3 "Level 3" 4 "Level 4" 5 "Level 5" 6 "OFF" 7 "Not Used";
VAL_ 890 ThirdRowRightSeatAutoDisplay_MM 0 "No display" 1 "Seat Auto ON" 2 "Seat Auto OFF" 3 "Not used";
VAL_ 890 ThirdRowLeftSeatAutoDisplay_MM 0 "No display" 1 "Seat Auto ON" 2 "Seat Auto OFF" 3 "Not used";
VAL_ 890 ClimRearRightSyncDisplay_MM 0 "No display" 1 "Sync mode ON" 2 "Sync mode OFF" 3 "Not used";
VAL_ 890 ClimRearLeftSyncDisplay_MM 0 "No display" 1 "Sync mode ON" 2 "Sync mode OFF" 3 "Not used";
VAL_ 890 ThirdRowLeftSeatStatus_MM 0 "Unavailable" 1 "OFF display" 2 "Heater Low display" 3 "Heater Middle display" 4 "Heater High display" 5 "Not used" 6 "Not used" 7 "Not used";
VAL_ 890 ThirdRowRightSeatStatus_MM 0 "Unavailable" 1 "OFF display" 2 "Heater Low display" 3 "Heater Middle display" 4 "Heater High display" 5 "Not used" 6 "Not used" 7 "Not used";
VAL_ 920 NavigationAlertDisplayRequest 0 "No Display Request" 1 "Speed Trap Alert Display Request" 2 "Dangerous Area Display Request" 3 "IncomingDangerousAreaDisplay" 4 "Not used" 5 "Not used" 6 "Not used" 7 "Not used";
VAL_ 945 CentralPanelMMSwitch 0 "All Button released" 1 "Button 1 pressed" 2 "Button 2 pressed" 3 "Button 3 pressed" 4 "Button 4 pressed" 5 "Button 5 pressed" 6 "Button 6 pressed" 7 "Button 7 pressed";
VAL_ 945 CPdisplayAvailability 0 "CentralPanel not ready to display" 1 "CentralPanel ready to display";
VAL_ 961 MMI_MultimediaState 0 "MMI Off" 1 "Welcome" 2 "MMI-ON partial On user HMI" 3 "MMI-ON partial Stand by" 4 "MMI-ON partial Dark" 5 "MMI-ON full On user HMI" 6 "MMI-ON full Stand by" 7 "MMI-ON full Dark";
VAL_ 987 ASAactivationState_MM 0 "Activated" 1 "Deactivated";
VAL_ 987 ADA1ActivationState_MM 0 "Activated" 1 "Deactivated";
VAL_ 987 VehicleStates_MM 0 "Sleeping" 1 "Not used" 2 "CutoffPending" 3 "AutoACC  - BatTempoLevel" 4 "Not used" 5 "IgnitionLevel" 6 "StartingInProgress" 7 "PowertrainRunning" 8 "AutoStart" 9 "EngineSystemStop" 10 "Not used" 11 "Not used" 12 "Not used" 13 "Not used" 14 "Not used" 15 "Unavailable";
VAL_ 987 AutoDimmingState_MM 0 "AutoDimming Not activated" 1 "AutoDimming activated";
VAL_ 987 MeterLanguageStatus_MM 0 "Not used" 1 "Language 1 to 253" 255 "Unavailable value";
VAL_ 1026 CPdisplayDayLuminosityRequest 30 "No request" 31 "Reset request";
VAL_ 1026 CPdisplayNightLuminosityRequest 30 "No request" 31 "Reset request";
VAL_ 1034 DiffLock_indicatorSignal_MM 0 "Diff lock indicator OFF" 1 "Diff lock indicator ON" 2 "Diff lock indicator Flash" 3 "Not used";
VAL_ 1034 AWD_SwitchSignal_IVI_MM 0 "automatic selection mode" 1 "fixed AWD mode" 2 "fixed 2WD mode" 3 "4 Lo Mode";
VAL_ 1034 AirSusp_IndicatorRequest_MM 0 "High:Grayout, Access:Grayout" 1 "High:Grayout, Access:OFF" 2 "High:Grayout, Access:ON" 3 "Reserve" 4 "High:OFF, Access:Grayout" 5 "High:OFF, Access:OFF" 6 "High:OFF, Access:ON" 7 "Reserve" 8 "High:ON, Access:Grayout" 9 "High:ON, Access:OFF" 10 "High:ON, Access:ON" 11 "Reserve" 12 "Reserve" 13 "Reserve" 14 "Reserve" 15 "Unavailable";
VAL_ 1034 AirSusp_HeightModestatus_MM 0 "Not Request" 1 "Standard Height Request" 2 "Hight Height Request" 3 "Reserve" 4 "Reserve" 5 "Standard Height Request blink" 6 "Hight Height Request  blink" 7 "Reserve";
VAL_ 1034 VDCActivationState_MM 0 "VDC is activated" 1 "VDC is deactivated";
VAL_ 1087 AirSUSP_ControlPanelRequest_FCP 0 "Not Request" 1 "Standard Height Request" 2 "High Height Request" 3 "Unavailable";
VAL_ 1135 AutoDimmingOffsetY0_MM 0 "Unavailable" 1 "Step 1" 2 "Step 2" 3 "Step 3" 4 "Step 4" 5 "Step 5" 6 "Step 6" 7 "Step 7" 8 "Step 8" 9 "Step 9" 10 "Step 10" 11 "Step 11" 12 "Step 12" 13 "Step 13" 14 "Step 14" 15 "Step 15";
VAL_ 1158 DayNightStatusForB_Switches_MM 0 "Conditionned backlight" 1 "Permanent backlight";
VAL_ 1158 ProbableCustomerFeedBackNeed_MM 0 "Customer feedback probably not needed" 1 "Customer feedback needed";
VAL_ 1217 Uniform_Symbol_099_displayed 0 "No Display" 1 "ActivateState1" 2 "ActivateState2" 3 "ActivateState3";
VAL_ 1217 Uniform_Symbol_098_displayed 0 "No Display" 1 "ActivateState1" 2 "ActivateState2" 3 "ActivateState3";
VAL_ 1217 Uniform_Symbol_097_displayed 0 "No Display" 1 "ActivateState1" 2 "ActivateState2" 3 "ActivateState3";
VAL_ 1217 Uniform_Symbol_096_displayed 0 "No Display" 1 "ActivateState1" 2 "ActivateState2" 3 "ActivateState3";
VAL_ 1217 Uniform_Symbol_103_displayed 0 "No Display" 1 "ActivateState1" 2 "ActivateState2" 3 "ActivateState3";
VAL_ 1217 Uniform_Symbol_102_displayed 0 "No Display" 1 "ActivateState1" 2 "ActivateState2" 3 "ActivateState3";
VAL_ 1217 Uniform_Symbol_101_displayed 0 "No Display" 1 "ActivateState1" 2 "ActivateState2" 3 "ActivateState3";
VAL_ 1217 Uniform_Symbol_100_displayed 0 "No Display" 1 "ActivateState1" 2 "ActivateState2" 3 "ActivateState3";
VAL_ 1217 Uniform_Symbol_107_displayed 0 "No Display" 1 "ActivateState1" 2 "ActivateState2" 3 "ActivateState3";
VAL_ 1217 Uniform_Symbol_106_displayed 0 "No Display" 1 "ActivateState1" 2 "ActivateState2" 3 "ActivateState3";
VAL_ 1217 Uniform_Symbol_105_displayed 0 "No Display" 1 "ActivateState1" 2 "ActivateState2" 3 "ActivateState3";
VAL_ 1217 Uniform_Symbol_104_displayed 0 "No Display" 1 "ActivateState1" 2 "ActivateState2" 3 "ActivateState3";
VAL_ 1217 Uniform_Symbol_111_displayed 0 "No Display" 1 "ActivateState1" 2 "ActivateState2" 3 "ActivateState3";
VAL_ 1217 Uniform_Symbol_110_displayed 0 "No Display" 1 "ActivateState1" 2 "ActivateState2" 3 "ActivateState3";
VAL_ 1217 Uniform_Symbol_109_displayed 0 "No Display" 1 "ActivateState1" 2 "ActivateState2" 3 "ActivateState3";
VAL_ 1217 Uniform_Symbol_108_displayed 0 "No Display" 1 "ActivateState1" 2 "ActivateState2" 3 "ActivateState3";
VAL_ 1217 Uniform_Symbol_115_displayed 0 "No Display" 1 "ActivateState1" 2 "ActivateState2" 3 "ActivateState3";
VAL_ 1217 Uniform_Symbol_114_displayed 0 "No Display" 1 "ActivateState1" 2 "ActivateState2" 3 "ActivateState3";
VAL_ 1217 Uniform_Symbol_113_displayed 0 "No Display" 1 "ActivateState1" 2 "ActivateState2" 3 "ActivateState3";
VAL_ 1217 Uniform_Symbol_112_displayed 0 "No Display" 1 "ActivateState1" 2 "ActivateState2" 3 "ActivateState3";
VAL_ 1217 Uniform_Symbol_119_displayed 0 "No Display" 1 "ActivateState1" 2 "ActivateState2" 3 "ActivateState3";
VAL_ 1217 Uniform_Symbol_118_displayed 0 "No Display" 1 "ActivateState1" 2 "ActivateState2" 3 "ActivateState3";
VAL_ 1217 Uniform_Symbol_117_displayed 0 "No Display" 1 "ActivateState1" 2 "ActivateState2" 3 "ActivateState3";
VAL_ 1217 Uniform_Symbol_116_displayed 0 "No Display" 1 "ActivateState1" 2 "ActivateState2" 3 "ActivateState3";
VAL_ 1217 Uniform_Symbol_123_displayed 0 "No Display" 1 "ActivateState1" 2 "ActivateState2" 3 "ActivateState3";
VAL_ 1217 Uniform_Symbol_122_displayed 0 "No Display" 1 "ActivateState1" 2 "ActivateState2" 3 "ActivateState3";
VAL_ 1217 Uniform_Symbol_121_displayed 0 "No Display" 1 "ActivateState1" 2 "ActivateState2" 3 "ActivateState3";
VAL_ 1217 Uniform_Symbol_120_displayed 0 "No Display" 1 "ActivateState1" 2 "ActivateState2" 3 "ActivateState3";
VAL_ 1217 Uniform_Symbol_127_displayed 0 "No Display" 1 "ActivateState1" 2 "ActivateState2" 3 "ActivateState3";
VAL_ 1217 Uniform_Symbol_126_displayed 0 "No Display" 1 "ActivateState1" 2 "ActivateState2" 3 "ActivateState3";
VAL_ 1217 Uniform_Symbol_125_displayed 0 "No Display" 1 "ActivateState1" 2 "ActivateState2" 3 "ActivateState3";
VAL_ 1217 Uniform_Symbol_124_displayed 0 "No Display" 1 "ActivateState1" 2 "ActivateState2" 3 "ActivateState3";
VAL_ 1222 Uniform_Symbol_131_displayed 0 "No Display" 1 "ActivateState1" 2 "ActivateState2" 3 "ActivateState3";
VAL_ 1222 Uniform_Symbol_130_displayed 0 "No Display" 1 "ActivateState1" 2 "ActivateState2" 3 "ActivateState3";
VAL_ 1222 Uniform_Symbol_129_displayed 0 "No Display" 1 "ActivateState1" 2 "ActivateState2" 3 "ActivateState3";
VAL_ 1222 Uniform_Symbol_128_displayed 0 "No Display" 1 "ActivateState1" 2 "ActivateState2" 3 "ActivateState3";
VAL_ 1222 Uniform_Symbol_135_displayed 0 "No Display" 1 "ActivateState1" 2 "ActivateState2" 3 "ActivateState3";
VAL_ 1222 Uniform_Symbol_134_displayed 0 "No Display" 1 "ActivateState1" 2 "ActivateState2" 3 "ActivateState3";
VAL_ 1222 Uniform_Symbol_133_displayed 0 "No Display" 1 "ActivateState1" 2 "ActivateState2" 3 "ActivateState3";
VAL_ 1222 Uniform_Symbol_132_displayed 0 "No Display" 1 "ActivateState1" 2 "ActivateState2" 3 "ActivateState3";
VAL_ 1222 Uniform_Symbol_139_displayed 0 "No Display" 1 "ActivateState1" 2 "ActivateState2" 3 "ActivateState3";
VAL_ 1222 Uniform_Symbol_138_displayed 0 "No Display" 1 "ActivateState1" 2 "ActivateState2" 3 "ActivateState3";
VAL_ 1222 Uniform_Symbol_137_displayed 0 "No Display" 1 "ActivateState1" 2 "ActivateState2" 3 "ActivateState3";
VAL_ 1222 Uniform_Symbol_136_displayed 0 "No Display" 1 "ActivateState1" 2 "ActivateState2" 3 "ActivateState3";
VAL_ 1222 Uniform_Symbol_143_displayed 0 "No Display" 1 "ActivateState1" 2 "ActivateState2" 3 "ActivateState3";
VAL_ 1222 Uniform_Symbol_142_displayed 0 "No Display" 1 "ActivateState1" 2 "ActivateState2" 3 "ActivateState3";
VAL_ 1222 Uniform_Symbol_141_displayed 0 "No Display" 1 "ActivateState1" 2 "ActivateState2" 3 "ActivateState3";
VAL_ 1222 Uniform_Symbol_140_displayed 0 "No Display" 1 "ActivateState1" 2 "ActivateState2" 3 "ActivateState3";
VAL_ 1222 Uniform_Symbol_147_displayed 0 "No Display" 1 "ActivateState1" 2 "ActivateState2" 3 "ActivateState3";
VAL_ 1222 Uniform_Symbol_146_displayed 0 "No Display" 1 "ActivateState1" 2 "ActivateState2" 3 "ActivateState3";
VAL_ 1222 Uniform_Symbol_145_displayed 0 "No Display" 1 "ActivateState1" 2 "ActivateState2" 3 "ActivateState3";
VAL_ 1222 Uniform_Symbol_144_displayed 0 "No Display" 1 "ActivateState1" 2 "ActivateState2" 3 "ActivateState3";
VAL_ 1222 Uniform_Symbol_151_displayed 0 "No Display" 1 "ActivateState1" 2 "ActivateState2" 3 "ActivateState3";
VAL_ 1222 Uniform_Symbol_150_displayed 0 "No Display" 1 "ActivateState1" 2 "ActivateState2" 3 "ActivateState3";
VAL_ 1222 Uniform_Symbol_149_displayed 0 "No Display" 1 "ActivateState1" 2 "ActivateState2" 3 "ActivateState3";
VAL_ 1222 Uniform_Symbol_148_displayed 0 "No Display" 1 "ActivateState1" 2 "ActivateState2" 3 "ActivateState3";
VAL_ 1222 Uniform_Symbol_155_displayed 0 "No Display" 1 "ActivateState1" 2 "ActivateState2" 3 "ActivateState3";
VAL_ 1222 Uniform_Symbol_154_displayed 0 "No Display" 1 "ActivateState1" 2 "ActivateState2" 3 "ActivateState3";
VAL_ 1222 Uniform_Symbol_153_displayed 0 "No Display" 1 "ActivateState1" 2 "ActivateState2" 3 "ActivateState3";
VAL_ 1222 Uniform_Symbol_152_displayed 0 "No Display" 1 "ActivateState1" 2 "ActivateState2" 3 "ActivateState3";
VAL_ 1222 Uniform_Symbol_159_displayed 0 "No Display" 1 "ActivateState1" 2 "ActivateState2" 3 "ActivateState3";
VAL_ 1222 Uniform_Symbol_158_displayed 0 "No Display" 1 "ActivateState1" 2 "ActivateState2" 3 "ActivateState3";
VAL_ 1222 Uniform_Symbol_157_displayed 0 "No Display" 1 "ActivateState1" 2 "ActivateState2" 3 "ActivateState3";
VAL_ 1222 Uniform_Symbol_156_displayed 0 "No Display" 1 "ActivateState1" 2 "ActivateState2" 3 "ActivateState3";
VAL_ 1229 Uniform_Symbol_163_displayed 0 "No Display" 1 "ActivateState1" 2 "ActivateState2" 3 "ActivateState3";
VAL_ 1229 Uniform_Symbol_162_displayed 0 "No Display" 1 "ActivateState1" 2 "ActivateState2" 3 "ActivateState3";
VAL_ 1229 Uniform_Symbol_161_displayed 0 "No Display" 1 "ActivateState1" 2 "ActivateState2" 3 "ActivateState3";
VAL_ 1229 Uniform_Symbol_160_displayed 0 "No Display" 1 "ActivateState1" 2 "ActivateState2" 3 "ActivateState3";
VAL_ 1229 Uniform_Symbol_167_displayed 0 "No Display" 1 "ActivateState1" 2 "ActivateState2" 3 "ActivateState3";
VAL_ 1229 Uniform_Symbol_166_displayed 0 "No Display" 1 "ActivateState1" 2 "ActivateState2" 3 "ActivateState3";
VAL_ 1229 Uniform_Symbol_165_displayed 0 "No Display" 1 "ActivateState1" 2 "ActivateState2" 3 "ActivateState3";
VAL_ 1229 Uniform_Symbol_164_displayed 0 "No Display" 1 "ActivateState1" 2 "ActivateState2" 3 "ActivateState3";
VAL_ 1229 Uniform_Symbol_171_displayed 0 "No Display" 1 "ActivateState1" 2 "ActivateState2" 3 "ActivateState3";
VAL_ 1229 Uniform_Symbol_170_displayed 0 "No Display" 1 "ActivateState1" 2 "ActivateState2" 3 "ActivateState3";
VAL_ 1229 Uniform_Symbol_169_displayed 0 "No Display" 1 "ActivateState1" 2 "ActivateState2" 3 "ActivateState3";
VAL_ 1229 Uniform_Symbol_168_displayed 0 "No Display" 1 "ActivateState1" 2 "ActivateState2" 3 "ActivateState3";
VAL_ 1229 Uniform_Symbol_175_displayed 0 "No Display" 1 "ActivateState1" 2 "ActivateState2" 3 "ActivateState3";
VAL_ 1229 Uniform_Symbol_174_displayed 0 "No Display" 1 "ActivateState1" 2 "ActivateState2" 3 "ActivateState3";
VAL_ 1229 Uniform_Symbol_173_displayed 0 "No Display" 1 "ActivateState1" 2 "ActivateState2" 3 "ActivateState3";
VAL_ 1229 Uniform_Symbol_172_displayed 0 "No Display" 1 "ActivateState1" 2 "ActivateState2" 3 "ActivateState3";
VAL_ 1229 Uniform_Symbol_179_displayed 0 "No Display" 1 "ActivateState1" 2 "ActivateState2" 3 "ActivateState3";
VAL_ 1229 Uniform_Symbol_178_displayed 0 "No Display" 1 "ActivateState1" 2 "ActivateState2" 3 "ActivateState3";
VAL_ 1229 Uniform_Symbol_177_displayed 0 "No Display" 1 "ActivateState1" 2 "ActivateState2" 3 "ActivateState3";
VAL_ 1229 Uniform_Symbol_176_displayed 0 "No Display" 1 "ActivateState1" 2 "ActivateState2" 3 "ActivateState3";
VAL_ 1229 Uniform_Symbol_183_displayed 0 "No Display" 1 "ActivateState1" 2 "ActivateState2" 3 "ActivateState3";
VAL_ 1229 Uniform_Symbol_182_displayed 0 "No Display" 1 "ActivateState1" 2 "ActivateState2" 3 "ActivateState3";
VAL_ 1229 Uniform_Symbol_181_displayed 0 "No Display" 1 "ActivateState1" 2 "ActivateState2" 3 "ActivateState3";
VAL_ 1229 Uniform_Symbol_180_displayed 0 "No Display" 1 "ActivateState1" 2 "ActivateState2" 3 "ActivateState3";
VAL_ 1229 Uniform_Symbol_187_displayed 0 "No Display" 1 "ActivateState1" 2 "ActivateState2" 3 "ActivateState3";
VAL_ 1229 Uniform_Symbol_186_displayed 0 "No Display" 1 "ActivateState1" 2 "ActivateState2" 3 "ActivateState3";
VAL_ 1229 Uniform_Symbol_185_displayed 0 "No Display" 1 "ActivateState1" 2 "ActivateState2" 3 "ActivateState3";
VAL_ 1229 Uniform_Symbol_184_displayed 0 "No Display" 1 "ActivateState1" 2 "ActivateState2" 3 "ActivateState3";
VAL_ 1229 Uniform_Symbol_191_displayed 0 "No Display" 1 "ActivateState1" 2 "ActivateState2" 3 "ActivateState3";
VAL_ 1229 Uniform_Symbol_190_displayed 0 "No Display" 1 "ActivateState1" 2 "ActivateState2" 3 "ActivateState3";
VAL_ 1229 Uniform_Symbol_189_displayed 0 "No Display" 1 "ActivateState1" 2 "ActivateState2" 3 "ActivateState3";
VAL_ 1229 Uniform_Symbol_188_displayed 0 "No Display" 1 "ActivateState1" 2 "ActivateState2" 3 "ActivateState3";
VAL_ 1237 CIDTouchControlAvailability_MM 0 "CID touch not ready" 1 "CID touch ready";
VAL_ 1237 MeterDisplayActivationStatus_MM 0 "OFF" 1 "Meter ON" 2 "IVI ON" 3 "Meter and IVI ON";
VAL_ 1237 IlluminationControlStatus 0 "Unavailable" 1 "Step1" 2 "Step2" 3 "Step3" 4 "Step4" 5 "Step5" 6 "Step6" 7 "Step7" 8 "Step8" 9 "Step9" 10 "Step10" 11 "Step11" 12 "Step12" 13 "Step13" 14 "Step14" 15 "Step15" 16 "Step16" 17 "Step17" 18 "Step18" 19 "Step19" 20 "Step20" 21 "Step21" 22 "Step22" 23 "Not used" 24 "Not used" 25 "Not used" 26 "Not used" 27 "Not used" 28 "Not used" 29 "Not used" 30 "Not used" 31 "Not used";
VAL_ 1237 IlluminationContStatusForCamera 0 "Unavailable" 1 "Step1" 2 "Step2" 3 "Step3" 4 "Step4" 5 "Step5" 6 "Step6" 7 "Step7" 8 "Step8" 9 "Step9" 10 "Step10" 11 "Step11" 12 "Step12" 13 "Step13" 14 "Step14" 15 "Step15" 16 "Step16" 17 "Step17" 18 "Step18" 19 "Step19" 20 "Step20" 21 "Step21" 22 "Step22" 23 "Not used" 24 "Not used" 25 "Not used" 26 "Not used" 27 "Not used" 28 "Not used" 29 "Not used" 30 "Not used" 31 "Not used";
VAL_ 1238 Uniform_Symbol_195_displayed 0 "No Display" 1 "ActivateState1" 2 "ActivateState2" 3 "ActivateState3";
VAL_ 1238 Uniform_Symbol_194_displayed 0 "No Display" 1 "ActivateState1" 2 "ActivateState2" 3 "ActivateState3";
VAL_ 1238 Uniform_Symbol_193_displayed 0 "No Display" 1 "ActivateState1" 2 "ActivateState2" 3 "ActivateState3";
VAL_ 1238 Uniform_Symbol_192_displayed 0 "No Display" 1 "ActivateState1" 2 "ActivateState2" 3 "ActivateState3";
VAL_ 1238 Uniform_Symbol_199_displayed 0 "No Display" 1 "ActivateState1" 2 "ActivateState2" 3 "ActivateState3";
VAL_ 1238 Uniform_Symbol_198_displayed 0 "No Display" 1 "ActivateState1" 2 "ActivateState2" 3 "ActivateState3";
VAL_ 1238 Uniform_Symbol_197_displayed 0 "No Display" 1 "ActivateState1" 2 "ActivateState2" 3 "ActivateState3";
VAL_ 1238 Uniform_Symbol_196_displayed 0 "No Display" 1 "ActivateState1" 2 "ActivateState2" 3 "ActivateState3";
VAL_ 1238 Uniform_Symbol_203_displayed 0 "No Display" 1 "ActivateState1" 2 "ActivateState2" 3 "ActivateState3";
VAL_ 1238 Uniform_Symbol_202_displayed 0 "No Display" 1 "ActivateState1" 2 "ActivateState2" 3 "ActivateState3";
VAL_ 1238 Uniform_Symbol_201_displayed 0 "No Display" 1 "ActivateState1" 2 "ActivateState2" 3 "ActivateState3";
VAL_ 1238 Uniform_Symbol_200_displayed 0 "No Display" 1 "ActivateState1" 2 "ActivateState2" 3 "ActivateState3";
VAL_ 1238 Uniform_Symbol_207_displayed 0 "No Display" 1 "ActivateState1" 2 "ActivateState2" 3 "ActivateState3";
VAL_ 1238 Uniform_Symbol_206_displayed 0 "No Display" 1 "ActivateState1" 2 "ActivateState2" 3 "ActivateState3";
VAL_ 1238 Uniform_Symbol_205_displayed 0 "No Display" 1 "ActivateState1" 2 "ActivateState2" 3 "ActivateState3";
VAL_ 1238 Uniform_Symbol_204_displayed 0 "No Display" 1 "ActivateState1" 2 "ActivateState2" 3 "ActivateState3";
VAL_ 1238 Uniform_Symbol_211_displayed 0 "No Display" 1 "ActivateState1" 2 "ActivateState2" 3 "ActivateState3";
VAL_ 1238 Uniform_Symbol_210_displayed 0 "No Display" 1 "ActivateState1" 2 "ActivateState2" 3 "ActivateState3";
VAL_ 1238 Uniform_Symbol_209_displayed 0 "No Display" 1 "ActivateState1" 2 "ActivateState2" 3 "ActivateState3";
VAL_ 1238 Uniform_Symbol_208_displayed 0 "No Display" 1 "ActivateState1" 2 "ActivateState2" 3 "ActivateState3";
VAL_ 1238 Uniform_Symbol_215_displayed 0 "No Display" 1 "ActivateState1" 2 "ActivateState2" 3 "ActivateState3";
VAL_ 1238 Uniform_Symbol_214_displayed 0 "No Display" 1 "ActivateState1" 2 "ActivateState2" 3 "ActivateState3";
VAL_ 1238 Uniform_Symbol_213_displayed 0 "No Display" 1 "ActivateState1" 2 "ActivateState2" 3 "ActivateState3";
VAL_ 1238 Uniform_Symbol_212_displayed 0 "No Display" 1 "ActivateState1" 2 "ActivateState2" 3 "ActivateState3";
VAL_ 1238 Uniform_Symbol_219_displayed 0 "No Display" 1 "ActivateState1" 2 "ActivateState2" 3 "ActivateState3";
VAL_ 1238 Uniform_Symbol_218_displayed 0 "No Display" 1 "ActivateState1" 2 "ActivateState2" 3 "ActivateState3";
VAL_ 1238 Uniform_Symbol_217_displayed 0 "No Display" 1 "ActivateState1" 2 "ActivateState2" 3 "ActivateState3";
VAL_ 1238 Uniform_Symbol_216_displayed 0 "No Display" 1 "ActivateState1" 2 "ActivateState2" 3 "ActivateState3";
VAL_ 1238 Uniform_Symbol_223_displayed 0 "No Display" 1 "ActivateState1" 2 "ActivateState2" 3 "ActivateState3";
VAL_ 1238 Uniform_Symbol_222_displayed 0 "No Display" 1 "ActivateState1" 2 "ActivateState2" 3 "ActivateState3";
VAL_ 1238 Uniform_Symbol_221_displayed 0 "No Display" 1 "ActivateState1" 2 "ActivateState2" 3 "ActivateState3";
VAL_ 1238 Uniform_Symbol_220_displayed 0 "No Display" 1 "ActivateState1" 2 "ActivateState2" 3 "ActivateState3";
VAL_ 1242 Multiform_symbol_001_displayed 0 "No Display" 1 "ActivateState1" 2 "ActivateState2" 3 "ActivateState3" 4 "ActivateState4" 5 "ActivateState5" 6 "ActivateState6" 7 "ActivateState7" 8 "ActivateState8" 9 "ActivateState9" 10 "ActivateState10" 11 "ActivateState11" 12 "ActivateState12" 13 "ActivateState13" 14 "ActivateState14" 15 "ActivateState15";
VAL_ 1242 Multiform_symbol_000_displayed 0 "No Display" 1 "ActivateState1" 2 "ActivateState2" 3 "ActivateState3" 4 "ActivateState4" 5 "ActivateState5" 6 "ActivateState6" 7 "ActivateState7" 8 "ActivateState8" 9 "ActivateState9" 10 "ActivateState10" 11 "ActivateState11" 12 "ActivateState12" 13 "ActivateState13" 14 "ActivateState14" 15 "ActivateState15";
VAL_ 1242 Multiform_symbol_003_displayed 0 "No Display" 1 "ActivateState1" 2 "ActivateState2" 3 "ActivateState3" 4 "ActivateState4" 5 "ActivateState5" 6 "ActivateState6" 7 "ActivateState7" 8 "ActivateState8" 9 "ActivateState9" 10 "ActivateState10" 11 "ActivateState11" 12 "ActivateState12" 13 "ActivateState13" 14 "ActivateState14" 15 "ActivateState15";
VAL_ 1242 Multiform_symbol_002_displayed 0 "No Display" 1 "ActivateState1" 2 "ActivateState2" 3 "ActivateState3" 4 "ActivateState4" 5 "ActivateState5" 6 "ActivateState6" 7 "ActivateState7" 8 "ActivateState8" 9 "ActivateState9" 10 "ActivateState10" 11 "ActivateState11" 12 "ActivateState12" 13 "ActivateState13" 14 "ActivateState14" 15 "ActivateState15";
VAL_ 1242 Multiform_symbol_005_displayed 0 "No Display" 1 "ActivateState1" 2 "ActivateState2" 3 "ActivateState3" 4 "ActivateState4" 5 "ActivateState5" 6 "ActivateState6" 7 "ActivateState7" 8 "ActivateState8" 9 "ActivateState9" 10 "ActivateState10" 11 "ActivateState11" 12 "ActivateState12" 13 "ActivateState13" 14 "ActivateState14" 15 "ActivateState15";
VAL_ 1242 Multiform_symbol_004_displayed 0 "No Display" 1 "ActivateState1" 2 "ActivateState2" 3 "ActivateState3" 4 "ActivateState4" 5 "ActivateState5" 6 "ActivateState6" 7 "ActivateState7" 8 "ActivateState8" 9 "ActivateState9" 10 "ActivateState10" 11 "ActivateState11" 12 "ActivateState12" 13 "ActivateState13" 14 "ActivateState14" 15 "ActivateState15";
VAL_ 1242 Multiform_symbol_007_displayed 0 "No Display" 1 "ActivateState1" 2 "ActivateState2" 3 "ActivateState3" 4 "ActivateState4" 5 "ActivateState5" 6 "ActivateState6" 7 "ActivateState7" 8 "ActivateState8" 9 "ActivateState9" 10 "ActivateState10" 11 "ActivateState11" 12 "ActivateState12" 13 "ActivateState13" 14 "ActivateState14" 15 "ActivateState15";
VAL_ 1242 Multiform_symbol_006_displayed 0 "No Display" 1 "ActivateState1" 2 "ActivateState2" 3 "ActivateState3" 4 "ActivateState4" 5 "ActivateState5" 6 "ActivateState6" 7 "ActivateState7" 8 "ActivateState8" 9 "ActivateState9" 10 "ActivateState10" 11 "ActivateState11" 12 "ActivateState12" 13 "ActivateState13" 14 "ActivateState14" 15 "ActivateState15";
VAL_ 1242 Multiform_symbol_009_displayed 0 "No Display" 1 "ActivateState1" 2 "ActivateState2" 3 "ActivateState3" 4 "ActivateState4" 5 "ActivateState5" 6 "ActivateState6" 7 "ActivateState7" 8 "ActivateState8" 9 "ActivateState9" 10 "ActivateState10" 11 "ActivateState11" 12 "ActivateState12" 13 "ActivateState13" 14 "ActivateState14" 15 "ActivateState15";
VAL_ 1242 Multiform_symbol_008_displayed 0 "No Display" 1 "ActivateState1" 2 "ActivateState2" 3 "ActivateState3" 4 "ActivateState4" 5 "ActivateState5" 6 "ActivateState6" 7 "ActivateState7" 8 "ActivateState8" 9 "ActivateState9" 10 "ActivateState10" 11 "ActivateState11" 12 "ActivateState12" 13 "ActivateState13" 14 "ActivateState14" 15 "ActivateState15";
VAL_ 1242 Multiform_symbol_011_displayed 0 "No Display" 1 "ActivateState1" 2 "ActivateState2" 3 "ActivateState3" 4 "ActivateState4" 5 "ActivateState5" 6 "ActivateState6" 7 "ActivateState7" 8 "ActivateState8" 9 "ActivateState9" 10 "ActivateState10" 11 "ActivateState11" 12 "ActivateState12" 13 "ActivateState13" 14 "ActivateState14" 15 "ActivateState15";
VAL_ 1242 Multiform_symbol_010_displayed 0 "No Display" 1 "ActivateState1" 2 "ActivateState2" 3 "ActivateState3" 4 "ActivateState4" 5 "ActivateState5" 6 "ActivateState6" 7 "ActivateState7" 8 "ActivateState8" 9 "ActivateState9" 10 "ActivateState10" 11 "ActivateState11" 12 "ActivateState12" 13 "ActivateState13" 14 "ActivateState14" 15 "ActivateState15";
VAL_ 1242 Multiform_symbol_013_displayed 0 "No Display" 1 "ActivateState1" 2 "ActivateState2" 3 "ActivateState3" 4 "ActivateState4" 5 "ActivateState5" 6 "ActivateState6" 7 "ActivateState7" 8 "ActivateState8" 9 "ActivateState9" 10 "ActivateState10" 11 "ActivateState11" 12 "ActivateState12" 13 "ActivateState13" 14 "ActivateState14" 15 "ActivateState15";
VAL_ 1242 Multiform_symbol_012_displayed 0 "No Display" 1 "ActivateState1" 2 "ActivateState2" 3 "ActivateState3" 4 "ActivateState4" 5 "ActivateState5" 6 "ActivateState6" 7 "ActivateState7" 8 "ActivateState8" 9 "ActivateState9" 10 "ActivateState10" 11 "ActivateState11" 12 "ActivateState12" 13 "ActivateState13" 14 "ActivateState14" 15 "ActivateState15";
VAL_ 1242 Multiform_symbol_015_displayed 0 "No Display" 1 "ActivateState1" 2 "ActivateState2" 3 "ActivateState3" 4 "ActivateState4" 5 "ActivateState5" 6 "ActivateState6" 7 "ActivateState7" 8 "ActivateState8" 9 "ActivateState9" 10 "ActivateState10" 11 "ActivateState11" 12 "ActivateState12" 13 "ActivateState13" 14 "ActivateState14" 15 "ActivateState15";
VAL_ 1242 Multiform_symbol_014_displayed 0 "No Display" 1 "ActivateState1" 2 "ActivateState2" 3 "ActivateState3" 4 "ActivateState4" 5 "ActivateState5" 6 "ActivateState6" 7 "ActivateState7" 8 "ActivateState8" 9 "ActivateState9" 10 "ActivateState10" 11 "ActivateState11" 12 "ActivateState12" 13 "ActivateState13" 14 "ActivateState14" 15 "ActivateState15";
VAL_ 1243 Multiform_symbol_017_displayed 0 "No Display" 1 "ActivateState1" 2 "ActivateState2" 3 "ActivateState3" 4 "ActivateState4" 5 "ActivateState5" 6 "ActivateState6" 7 "ActivateState7" 8 "ActivateState8" 9 "ActivateState9" 10 "ActivateState10" 11 "ActivateState11" 12 "ActivateState12" 13 "ActivateState13" 14 "ActivateState14" 15 "ActivateState15";
VAL_ 1243 Multiform_symbol_016_displayed 0 "No Display" 1 "ActivateState1" 2 "ActivateState2" 3 "ActivateState3" 4 "ActivateState4" 5 "ActivateState5" 6 "ActivateState6" 7 "ActivateState7" 8 "ActivateState8" 9 "ActivateState9" 10 "ActivateState10" 11 "ActivateState11" 12 "ActivateState12" 13 "ActivateState13" 14 "ActivateState14" 15 "ActivateState15";
VAL_ 1243 Multiform_symbol_019_displayed 0 "No Display" 1 "ActivateState1" 2 "ActivateState2" 3 "ActivateState3" 4 "ActivateState4" 5 "ActivateState5" 6 "ActivateState6" 7 "ActivateState7" 8 "ActivateState8" 9 "ActivateState9" 10 "ActivateState10" 11 "ActivateState11" 12 "ActivateState12" 13 "ActivateState13" 14 "ActivateState14" 15 "ActivateState15";
VAL_ 1243 Multiform_symbol_018_displayed 0 "No Display" 1 "ActivateState1" 2 "ActivateState2" 3 "ActivateState3" 4 "ActivateState4" 5 "ActivateState5" 6 "ActivateState6" 7 "ActivateState7" 8 "ActivateState8" 9 "ActivateState9" 10 "ActivateState10" 11 "ActivateState11" 12 "ActivateState12" 13 "ActivateState13" 14 "ActivateState14" 15 "ActivateState15";
VAL_ 1243 Multiform_symbol_021_displayed 0 "No Display" 1 "ActivateState1" 2 "ActivateState2" 3 "ActivateState3" 4 "ActivateState4" 5 "ActivateState5" 6 "ActivateState6" 7 "ActivateState7" 8 "ActivateState8" 9 "ActivateState9" 10 "ActivateState10" 11 "ActivateState11" 12 "ActivateState12" 13 "ActivateState13" 14 "ActivateState14" 15 "ActivateState15";
VAL_ 1243 Multiform_symbol_020_displayed 0 "No Display" 1 "ActivateState1" 2 "ActivateState2" 3 "ActivateState3" 4 "ActivateState4" 5 "ActivateState5" 6 "ActivateState6" 7 "ActivateState7" 8 "ActivateState8" 9 "ActivateState9" 10 "ActivateState10" 11 "ActivateState11" 12 "ActivateState12" 13 "ActivateState13" 14 "ActivateState14" 15 "ActivateState15";
VAL_ 1243 Multiform_symbol_023_displayed 0 "No Display" 1 "ActivateState1" 2 "ActivateState2" 3 "ActivateState3" 4 "ActivateState4" 5 "ActivateState5" 6 "ActivateState6" 7 "ActivateState7" 8 "ActivateState8" 9 "ActivateState9" 10 "ActivateState10" 11 "ActivateState11" 12 "ActivateState12" 13 "ActivateState13" 14 "ActivateState14" 15 "ActivateState15";
VAL_ 1243 Multiform_symbol_022_displayed 0 "No Display" 1 "ActivateState1" 2 "ActivateState2" 3 "ActivateState3" 4 "ActivateState4" 5 "ActivateState5" 6 "ActivateState6" 7 "ActivateState7" 8 "ActivateState8" 9 "ActivateState9" 10 "ActivateState10" 11 "ActivateState11" 12 "ActivateState12" 13 "ActivateState13" 14 "ActivateState14" 15 "ActivateState15";
VAL_ 1243 Multiform_symbol_025_displayed 0 "No Display" 1 "ActivateState1" 2 "ActivateState2" 3 "ActivateState3" 4 "ActivateState4" 5 "ActivateState5" 6 "ActivateState6" 7 "ActivateState7" 8 "ActivateState8" 9 "ActivateState9" 10 "ActivateState10" 11 "ActivateState11" 12 "ActivateState12" 13 "ActivateState13" 14 "ActivateState14" 15 "ActivateState15";
VAL_ 1243 Multiform_symbol_024_displayed 0 "No Display" 1 "ActivateState1" 2 "ActivateState2" 3 "ActivateState3" 4 "ActivateState4" 5 "ActivateState5" 6 "ActivateState6" 7 "ActivateState7" 8 "ActivateState8" 9 "ActivateState9" 10 "ActivateState10" 11 "ActivateState11" 12 "ActivateState12" 13 "ActivateState13" 14 "ActivateState14" 15 "ActivateState15";
VAL_ 1243 Multiform_symbol_027_displayed 0 "No Display" 1 "ActivateState1" 2 "ActivateState2" 3 "ActivateState3" 4 "ActivateState4" 5 "ActivateState5" 6 "ActivateState6" 7 "ActivateState7" 8 "ActivateState8" 9 "ActivateState9" 10 "ActivateState10" 11 "ActivateState11" 12 "ActivateState12" 13 "ActivateState13" 14 "ActivateState14" 15 "ActivateState15";
VAL_ 1243 Multiform_symbol_026_displayed 0 "No Display" 1 "ActivateState1" 2 "ActivateState2" 3 "ActivateState3" 4 "ActivateState4" 5 "ActivateState5" 6 "ActivateState6" 7 "ActivateState7" 8 "ActivateState8" 9 "ActivateState9" 10 "ActivateState10" 11 "ActivateState11" 12 "ActivateState12" 13 "ActivateState13" 14 "ActivateState14" 15 "ActivateState15";
VAL_ 1243 Multiform_symbol_029_displayed 0 "No Display" 1 "ActivateState1" 2 "ActivateState2" 3 "ActivateState3" 4 "ActivateState4" 5 "ActivateState5" 6 "ActivateState6" 7 "ActivateState7" 8 "ActivateState8" 9 "ActivateState9" 10 "ActivateState10" 11 "ActivateState11" 12 "ActivateState12" 13 "ActivateState13" 14 "ActivateState14" 15 "ActivateState15";
VAL_ 1243 Multiform_symbol_028_displayed 0 "No Display" 1 "ActivateState1" 2 "ActivateState2" 3 "ActivateState3" 4 "ActivateState4" 5 "ActivateState5" 6 "ActivateState6" 7 "ActivateState7" 8 "ActivateState8" 9 "ActivateState9" 10 "ActivateState10" 11 "ActivateState11" 12 "ActivateState12" 13 "ActivateState13" 14 "ActivateState14" 15 "ActivateState15";
VAL_ 1243 Multiform_symbol_031_displayed 0 "No Display" 1 "ActivateState1" 2 "ActivateState2" 3 "ActivateState3" 4 "ActivateState4" 5 "ActivateState5" 6 "ActivateState6" 7 "ActivateState7" 8 "ActivateState8" 9 "ActivateState9" 10 "ActivateState10" 11 "ActivateState11" 12 "ActivateState12" 13 "ActivateState13" 14 "ActivateState14" 15 "ActivateState15";
VAL_ 1243 Multiform_symbol_030_displayed 0 "No Display" 1 "ActivateState1" 2 "ActivateState2" 3 "ActivateState3" 4 "ActivateState4" 5 "ActivateState5" 6 "ActivateState6" 7 "ActivateState7" 8 "ActivateState8" 9 "ActivateState9" 10 "ActivateState10" 11 "ActivateState11" 12 "ActivateState12" 13 "ActivateState13" 14 "ActivateState14" 15 "ActivateState15";
VAL_ 1248 SteeringADACBackCommand 0 "Button released" 1 "Button pressed";
VAL_ 1248 SteeringADACDownCommand 0 "Button released" 1 "Button pressed";
VAL_ 1248 SteeringADACUpCommand 0 "Button released" 1 "Button pressed";
VAL_ 1248 MultimediaFactorySettingReset 0 "No Reset" 1 "Factory Reset Requested";
VAL_ 1248 ClusterCurrentDisplayMode 0 "Home mode" 1 "Vehicle mode" 2 "Audio mode" 3 "Media mode" 4 "Phone mode" 5 "Vehicle setting mode" 6 "Audio setting mode" 7 "Phone setting mode";
VAL_ 1248 ClusterCurrentDisplayAlert 0 "No Alert display" 1 "Alert Displayed on Meter";
VAL_ 1248 SteeringADACOkCommand 0 "Button released" 1 "Button pressed";
VAL_ 1248 SetTimeEvent_ClockDisplay 0 "Set current time not requested" 1 "Set current time requested";
VAL_ 1280 R_ANC_ActivationRequest_FCP 0 "No R-ANC request" 1 "R-ANC activation request" 2 "R-ANC deactivation request" 3 "Unavailable";
VAL_ 1280 IoniserAutoLaunchReq_FCP 0 "No request" 1 "Activation request" 2 "Deactivation request" 3 "Reset request";
VAL_ 1280 R_ANC_ModeSwitchRequest_FCP 0 "No request" 1 "Mode1_Switching request all seat mode" 2 "Mode2_Switching request front seat mode" 3 "Mode3_Switching request rear seat mode" 4 "Mode4_Switching request front Left seat mode" 5 "Mode5_Switching request front Right seat mode" 6 "Not Used" 7 "Unavailable";
VAL_ 1283 RRLeftMassageActivationReq_RCP 0 "No request" 1 "Activation request" 2 "Deactivation request" 3 "Not used";
VAL_ 1283 RRLeftLumbarMovingReq_Z_Axis_RCP 0 "No request" 1 "Upward ON" 2 "Downward ON" 3 "Not Used";
VAL_ 1283 RRLeftLumbarMovingReq_X_Axis_RCP 0 "No request" 1 "Forward ON" 2 "Backward ON" 3 "Not Used";
VAL_ 1283 RRLeftFrontHeightMovingReq_RCP 0 "No request" 1 "Upward ON" 2 "Downward ON" 3 "Not Used";
VAL_ 1283 RRLeftOttomanMovingReq_RCP 0 "No request" 1 "Upward ON" 2 "Downward ON" 3 "Not Used";
VAL_ 1283 RRLeftMassageVelocityReq_RCP 0 "No request" 1 "Velocity 1 requested" 2 "Velocity 2 requested" 3 "Velocity 3 requested" 4 "Velocity 4 requested" 5 "Velocity 5 requested" 6 "Not Used" 7 "Not Used";
VAL_ 1283 RRLeftMassageIntensityReq_RCP 0 "No request" 1 "Intensity 1 requested" 2 "Intensity 2 requested" 3 "Intensity 3 requested" 4 "Intensity 4 requested" 5 "Intensity 5 requested" 6 "Not used" 7 "Not used";
VAL_ 1283 RRLeftSlideMovingReq_RCP 0 "No request" 1 "Forward ON" 2 "Backward ON" 3 "Not Used";
VAL_ 1283 RRLeftReclinerMovingReq_RCP 0 "No request" 1 "Forward ON" 2 "Backward ON" 3 "Not Used";
VAL_ 1283 RRLeftMassageProgramReq_RCP 0 "No request" 1 "Program 1 requested" 2 "Program 2 requested" 3 "Program 3 requested" 4 "Program 4 requested" 5 "Program 5 requested" 6 "Program 6 requested" 7 "Program 7 requested" 8 "Program 8 requested" 9 "Program 9 requested" 10 "Program 10 requested" 11 "Program 11 requested" 12 "Program 12 requested" 13 "Program 13 requested" 14 "Program 14 requested" 15 "Not used";
VAL_ 1283 RRLeftUpperbackrestMovingReq_RCP 0 "No request" 1 "Forward ON" 2 "Backward ON" 3 "Not Used";
VAL_ 1283 RRRightMassageIntensityReq_RCP 0 "No request" 1 "Intensity 1 requested" 2 "Intensity 2 requested" 3 "Intensity 3 requested" 4 "Intensity 4 requested" 5 "Intensity 5 requested" 6 "Not used" 7 "Not used";
VAL_ 1283 RRRightMassageVelocityReq_RCP 0 "No request" 1 "Velocity 1 requested" 2 "Velocity 2 requested" 3 "Velocity 3 requested" 4 "Velocity 4 requested" 5 "Velocity 5 requested" 6 "Not Used" 7 "Not Used";
VAL_ 1283 RRRightMassageActivationReq_RCP 0 "No request" 1 "Activation request" 2 "Deactivation request" 3 "Not used";
VAL_ 1283 RRRightLumbarMovReq_Z_Axis_RCP 0 "No request" 1 "Upward ON" 2 "Downward ON" 3 "Not Used";
VAL_ 1283 RRRightLumbarMovReq_X_Axis_RCP 0 "No request" 1 "Forward ON" 2 "Backward ON" 3 "Not Used";
VAL_ 1283 RRRightFrontHeightMovingReq_RCP 0 "No request" 1 "Upward ON" 2 "Downward ON" 3 "Not Used";
VAL_ 1283 RRRightReclinerMovingReq_RCP 0 "No request" 1 "Forward ON" 2 "Backward ON" 3 "Not Used";
VAL_ 1283 RRRightOttomanMovingReq_RCP 0 "No request" 1 "Upward ON" 2 "Downward ON" 3 "Not Used";
VAL_ 1283 RRRightMassageProgramReq_RCP 0 "No request" 1 "Program 1 requested" 2 "Program 2 requested" 3 "Program 3 requested" 4 "Program 4 requested" 5 "Program 5 requested" 6 "Program 6 requested" 7 "Program 7 requested" 8 "Program 8 requested" 9 "Program 9 requested" 10 "Program 10 requested" 11 "Program 11 requested" 12 "Program 12 requested" 13 "Program 13 requested" 14 "Program 14 requested" 15 "Not used";
VAL_ 1283 RearRightAutoReturnReq_RCP 0 "No request" 1 "Activation request" 2 "Deactivation request" 3 "Not Used";
VAL_ 1283 RearLeftAutoReturnReq_RCP 0 "No request" 1 "Activation request" 2 "Deactivation request" 3 "Not Used";
VAL_ 1283 RRRightUpperbackrestMovReq_RCP 0 "No request" 1 "Forward ON" 2 "Backward ON" 3 "Not Used";
VAL_ 1283 RRRightSlideMovingReq_RCP 0 "No request" 1 "Forward ON" 2 "Backward ON" 3 "Not Used";
VAL_ 1287 ClimRightTempDisplay_MM 0 "No display" 8 "Display Lo" 10 "Display Hi";
VAL_ 1287 ClimTempDisplay_MM 0 "No display" 8 "Display Lo" 10 "Display Hi";
VAL_ 1287 ClimFlowDistrDisplay_MM 0 "No display" 1 "Feet" 2 "Aerator" 3 "Feet + Aerator" 4 "Mild flow" 5 "Feet + Mild flow" 6 "Mild flow + Aerator" 7 "Feet + Aerator Mild flow" 8 "Defrost" 9 "Feet + Defrost" 10 "Aerator + Defrost" 11 "Feet + Aerator + Defrost" 12 "Mild flow + Defrost" 13 "Feet + Mild flow + Defrost" 14 "Aerator + Mild flow + Defrost" 15 "Feet + Aerator + Mild flow + Defrost";
VAL_ 1287 ClimBlowerLevelDisplay_MM 0 "No display" 1 "Level 1" 2 "Level 2" 3 "Level 3" 4 "Level 4" 5 "Level 5" 6 "Level 6" 7 "Level 7" 8 "Level 8" 9 "Level 9" 10 "Level 10" 11 "Level 11" 12 "Level 12" 13 "Level 13" 14 "Level 14" 15 "Blower Off";
VAL_ 1287 ClimLinkMaxFanSpeedAutoDisp_MM 0 "No display" 1 "Level 1" 2 "Level 2" 3 "Level 3" 4 "Level 4" 5 "Level 5" 6 "OFF" 7 "Not used";
VAL_ 1287 ClimHumidSensorSensitivDisp_MM 0 "No display" 1 "Level 1" 2 "Level 2" 3 "Level 3" 4 "Level 4" 5 "Level 5" 6 "OFF" 7 "Not used";
VAL_ 1287 ClimLastFuncModiByCustomer_v2_MM 0 "No last action" 1 "Temperature" 2 "Not used" 3 "Rear defrost" 4 "Clearness" 5 "Flow Distribution" 6 "Forced Recycling" 7 "OFF Button" 8 "Blower Level" 9 "Seat heating / ventilating" 10 "Auto" 11 "AC" 12 "Auto Recycling" 13 "Front defrost" 14 "Sync" 15 "Steering Wheel Heater";
VAL_ 1287 ClimAutoDisplay_MM 0 "No display" 1 "Auto activated" 2 "Auto not activated" 3 "Not used";
VAL_ 1287 ClimACDisplay_MM 0 "No display" 1 "AC ON" 2 "AC OFF" 3 "Not used";
VAL_ 1287 ClimRightFlowDistrDisplay_MM 0 "No display" 1 "Feet" 2 "Vent" 3 "Feet + Vent" 4 "Defrost" 5 "Defrost + Feet" 6 "Defrost + Vent" 7 "Defrost + Vent + Feet";
VAL_ 1287 ClimRightAutoDisplay_MM 0 "No display" 1 "Auto ON" 2 "Auto OFF" 3 "Not Used";
VAL_ 1287 ClimForestDisplay_MM 0 "No display" 1 "Forest ON" 2 "Forest OFF" 3 "Not used";
VAL_ 1287 ClimDriverZoneDisplay_MM 0 "No display" 1 "Driver zone ON" 2 "Driver zone OFF" 3 "Not used";
VAL_ 1287 ClimClearnessDisplay_MM 0 "No display" 1 "Clearness ON" 2 "Clearness OFF" 3 "Not Used";
VAL_ 1287 ClimClearnessDisplayStatus_MM 0 "Function not available" 1 "Function available";
VAL_ 1287 ClimCabinTempDisplayUnit_MM 0 "display mode in °C" 1 "display mode in °F";
VAL_ 1287 ClimBlowingLevelDisplayStatus_MM 0 "Function not available" 1 "Function available";
VAL_ 1287 ClimACDisplayStatus_MM 0 "Function not available" 1 "Function available";
VAL_ 1287 ClimSyncDisplay_MM 0 "No display" 1 "Sync mode ON" 2 "Sync mode OFF" 3 "Not Used";
VAL_ 1287 ClimSyncDisplayStatus_MM 0 "Function not available" 1 "Function available";
VAL_ 1287 ClimRightTempDisplayStatus_MM 0 "Function not available" 1 "Function available";
VAL_ 1287 ClimRightFloDistDisplayStatus_MM 0 "Function not available" 1 "Function available";
VAL_ 1287 ClimOFFModeDisplayStatus_MM 0 "Function not available" 1 "Function available";
VAL_ 1287 ClimOFFModeDisplay_MM 0 "No Display" 1 "OFF Mode Activated Display";
VAL_ 1287 ClimForestDisplayStatus_MM 0 "Function not available" 1 "Function available";
VAL_ 1287 ClimFlowDistrDisplayStatus_MM 0 "Function not available" 1 "Function available";
VAL_ 1287 ClimDriverZoneDisplayStatus_MM 0 "Function not available" 1 "Function available";
VAL_ 1288 ClimRearLeftTempDisplay_MM 0 "No display" 8 "Display Lo" 10 "Display Hi";
VAL_ 1288 ClimRearRightTempDisplay_MM 0 "No display" 8 "Display Lo" 10 "Display Hi";
VAL_ 1288 ClimRearRightBlowLevelDisplay_MM 0 "No display" 1 "Level 1" 2 "Level 2" 3 "Level 3" 4 "Level 4" 5 "Level 5" 6 "Level 6" 7 "Level 7" 8 "Level 8" 9 "Level 9" 10 "Level 10" 11 "Level 11" 12 "Level 12" 13 "Level 13" 14 "Level 14" 15 "Blower OFF";
VAL_ 1288 ClimRearLeftBlowLevelDisplay_MM 0 "No display" 1 "Level 1" 2 "Level 2" 3 "Level 3" 4 "Level 4" 5 "Level 5" 6 "Level 6" 7 "Level 7" 8 "Level 8" 9 "Level 9" 10 "Level 10" 11 "Level 11" 12 "Level 12" 13 "Level 13" 14 "Level 14" 15 "Blower OFF";
VAL_ 1288 ClimRearLeftFlowDistrDisplay_MM 0 "No display" 1 "Feet" 2 "Vent" 3 "Feet + Vent" 4 "Defrost" 5 "Defrost + Feet" 6 "Defrost + Vent" 7 "Defrost + Vent + Feet";
VAL_ 1288 ClimLinkPriorHeatStrgAutoDisp_MM 0 "No display" 1 "Level 1" 2 "Level 2" 3 "Level 3" 4 "Level 4" 5 "Level 5" 6 "OFF" 7 "Not used";
VAL_ 1288 ClimLinkPrioRearSeatsAutoDisp_MM 0 "No display" 1 "Level 1" 2 "Level 2" 3 "Level 3" 4 "Level 4" 5 "Level 5" 6 "OFF" 7 "Not used";
VAL_ 1288 SecondRowLeftSeatStatus_MM 0 "Unavailable" 1 "OFF display" 2 "Heater Low display" 3 "Heater Middle display" 4 "Heater High display" 5 "Ventilated Low display" 6 "Ventilated Middle display" 7 "Ventilated High display";
VAL_ 1288 ClimVariableAirFlowDisplay_MM 0 "No display" 1 "Level 1" 2 "Level 2" 3 "Level 3" 4 "Level 4" 5 "Level 5" 6 "OFF" 7 "Not used";
VAL_ 1288 ClimRearRightFlowDistrDisplay_MM 0 "No display" 1 "Feet" 2 "Vent" 3 "Feet + Vent" 4 "Defrost" 5 "Defrost + Feet" 6 "Defrost + Vent" 7 "Defrost + Vent + Feet";
VAL_ 1288 ClimRearLockStatus_MM 0 "No display" 1 "Rear climate lock display" 2 "Rear climate unlock display" 3 "Not used";
VAL_ 1288 ClimRearLeftAutoDisplay_MM 0 "No display" 1 "Auto ON" 2 "Auto OFF" 3 "Not used";
VAL_ 1288 SecondRowRightSeatStatus_MM 0 "Unavailable" 1 "OFF display" 2 "Heater Low display" 3 "Heater Middle display" 4 "Heater High display" 5 "Ventilated Low display" 6 "Ventilated Middle display" 7 "Ventilated High display";
VAL_ 1288 ClimHeatedSteerWheelDispStatu_MM 0 "Function not available" 1 "Function available";
VAL_ 1288 RearSeatsLockStatus_MM 0 "Unavailable" 1 "Thermal comfort lock display" 2 "Thermal comfort unlock display" 3 "Not Used";
VAL_ 1288 SecondRowRightSeatAutoDisplay_MM 0 "No display" 1 "Seat Auto ON" 2 "Seat Auto OFF" 3 "Not used";
VAL_ 1288 SecondRowLeftSeatAutoDisplay_MM 0 "No display" 1 "Seat Auto ON" 2 "Seat Auto OFF" 3 "Not used";
VAL_ 1288 SecondRowRightSeatDispStatus_MM 0 "Function not available" 1 "Function available";
VAL_ 1288 SecondRowLeftSeatDispStatus_MM 0 "Function not available" 1 "Function available";
VAL_ 1288 ClimTempDisplayStatus_MM 0 "Function not available" 1 "Function available";
VAL_ 1288 ClimRearRightTempDispStatus_MM 0 "Function not available" 1 "Function available";
VAL_ 1288 ClimRearRightFloDistDispStatu_MM 0 "Function not available" 1 "Function available";
VAL_ 1288 ClimRearOFFModeDisplay_MM 0 "No display" 1 "OFF Mode Activated Display";
VAL_ 1288 ClimRearLeftTempDisplayStatus_MM 0 "Function not available" 1 "Function available";
VAL_ 1288 ClimRearLeftFlowDistDispStatu_MM 0 "Function not available" 1 "Function available";
VAL_ 1289 RRRightMassageProgramState_MM 0 "Massage not Running" 1 "Program 1 running" 2 "Program 2 running" 3 "Program 3 running" 4 "Program 4 running" 5 "Program 5 running" 6 "Program 6 running" 7 "Program 7 running" 8 "Program 8 running" 9 "Program 9 running" 10 "Program 10 running" 11 "Program 11 running" 12 "Program 12 running" 13 "Program 13 running" 14 "Program 14 running" 15 "Not used";
VAL_ 1289 RRLeftMassageProgramState_MM 0 "Massage not Running" 1 "Program 1 running" 2 "Program 2 running" 3 "Program 3 running" 4 "Program 4 running" 5 "Program 5 running" 6 "Program 6 running" 7 "Program 7 running" 8 "Program 8 running" 9 "Program 9 running" 10 "Program 10 running" 11 "Program 11 running" 12 "Program 12 running" 13 "Program 13 running" 14 "Program 14 running" 15 "Not used";
VAL_ 1289 ClimLinkPrioritFLSeatAutoDisp_MM 0 "No display" 1 "Level 1" 2 "Level 2" 3 "Level 3" 4 "Level 4" 5 "Level 5" 6 "OFF" 7 "Not used";
VAL_ 1289 ClimAQSSensitivityDisplay_MM 0 "No display" 1 "Level 1" 2 "Level 2" 3 "Level 3" 4 "Level 4" 5 "Level 5" 6 "OFF" 7 "Not used";
VAL_ 1289 RRLeftMassageIntensityState_MM 0 "No intensity" 1 "Intensity 1" 2 "Intensity 2" 3 "Intensity 3" 4 "Intensity 4" 5 "Intensity 5" 6 "Not Used" 7 "Not Used";
VAL_ 1289 FrontRightSeatStatus_MM 0 "Unavailable" 1 "OFF display" 2 "Heater Low display" 3 "Heater Middle display" 4 "Heater High display" 5 "Ventilated Low display" 6 "Ventilated Middle display" 7 "Ventilated High display";
VAL_ 1289 FrontLeftSeatStatus_MM 0 "Unavailable" 1 "OFF display" 2 "Heater Low display" 3 "Heater Middle display" 4 "Heater High display" 5 "Ventilated Low display" 6 "Ventilated Middle display" 7 "Ventilated High display";
VAL_ 1289 RRLeftMassageVelocityState_MM 0 "No velocity" 1 "velocity 1" 2 "velocity 2" 3 "velocity 3" 4 "velocity 4" 5 "velocity 5" 6 "Not Used" 7 "Not Used";
VAL_ 1289 RRRightMassageIntensityState_MM 0 "No intensity" 1 "Intensity 1" 2 "Intensity 2" 3 "Intensity 3" 4 "Intensity 4" 5 "Intensity 5" 6 "Not Used" 7 "Not Used";
VAL_ 1289 ClimForcedRecyDisplay_MM 0 "No display" 1 "Recycling On" 2 "Recycling OFF" 3 "Not Used";
VAL_ 1289 ClimForcedFreshDisplay_MM 0 "No display" 1 "Fresh ON" 2 "Fresh OFF" 3 "Not Used";
VAL_ 1289 ClimAutoRecyclingDisplay_MM 0 "Unavailable value" 1 "Automatic Recycling not in progress" 2 "Automatic Recycling in progress" 3 "Not Used";
VAL_ 1289 RRRightMassageVelocityState_MM 0 "No velocity" 1 "velocity 1" 2 "velocity 2" 3 "velocity 3" 4 "velocity 4" 5 "velocity 5" 6 "Not Used" 7 "Not Used";
VAL_ 1289 FrontRightSeatAutoDisplay_MM 0 "No display" 1 "Seat Auto ON" 2 "Seat Auto OFF" 3 "Not used";
VAL_ 1289 FrontLeftSeatAutoDisplay_MM 0 "No display" 1 "Seat Auto ON" 2 "Seat Auto OFF" 3 "Not used";
VAL_ 1289 ClimRearDefrostDisplay_MM 0 "No display" 1 "Rear defrost ON" 2 "Rear defrost OFF" 3 "Not Used";
VAL_ 1289 ClimFrontDefrostDisplay_MM 0 "No display" 1 "Front defrost ON" 2 "Front defrost OFF" 3 "Not Used";
VAL_ 1289 ClimRearDefrostDisplayStatus_MM 0 "Function not available" 1 "Function available";
VAL_ 1289 ClimFrontDefrostDisplayStatus_MM 0 "Function not available" 1 "Function available";
VAL_ 1289 ClimForcedRecyDisplayStatus_MM 0 "Function not available" 1 "Function available";
VAL_ 1289 ClimForcedFreshDisplayStatus_MM 0 "Function not available" 1 "Function available";
VAL_ 1289 ClimAutoRecyDisplayStatus_MM 0 "Function not available" 1 "Function available";
VAL_ 1289 IoniserAutoLaunchState_MM 0 "Unavailable" 1 "Auto launch activated" 2 "Auto launch not activated" 3 "Not used";
VAL_ 1289 FrontRightSeatDisplayStatus_MM 0 "Function not available" 1 "Function available";
VAL_ 1289 FrontLeftSeatDisplayStatus_MM 0 "Function not available" 1 "Function available";
VAL_ 1297 PowerTrainSettingState_MM 0 "Mode 1 (Standard)" 1 "Mode 2 (Sport)" 2 "Mode 3 (Eco)" 3 "Mode 4 (Snow)" 4 "Mode 5" 5 "Mode 6" 6 "Mode 7" 7 "Mode 8" 8 "Mode 9" 9 "Mode 10" 10 "Mode 11" 11 "Mode 12" 12 "Mode 13" 13 "Mode 14" 14 "Not used" 15 "Not used";
VAL_ 1297 DriveModeState_MM 0 "Mode 0" 1 "Mode 1" 2 "Mode 2" 3 "Mode 3" 4 "Mode 4" 5 "Mode 5" 6 "Mode 6" 7 "Mode 7" 8 "Mode 8" 9 "Mode 9" 10 "Mode 10" 11 "Mode 11" 12 "Mode 12" 13 "Mode 13" 14 "Mode 14" 15 "Mode 15" 16 "Mode 16" 17 "Mode 17" 18 "Mode 18" 19 "Mode 19" 20 "Mode 20" 21 "Mode 21" 22 "Mode 22" 23 "Mode 23" 24 "Mode 24" 25 "Mode 25" 26 "Mode 26" 27 "Mode 27" 28 "Mode 28" 29 "Mode 29" 30 "Mode 30" 31 "Unavailable";
VAL_ 1297 VDCSettingState_MM 0 "Mode1" 1 "Mode2" 2 "Mode3" 3 "Mode4" 4 "Mode5" 5 "Mode6" 6 "Mode7" 7 "Mode8" 8 "Mode9" 9 "Mode10" 10 "Mode11" 11 "Mode12" 12 "Mode13" 13 "Mode14" 14 "Not used" 15 "Not used";
VAL_ 1297 SteeringSettingState_MM 0 "Mode EPS 1 Normal and Normal" 1 "Mode EPS 2 Normal and Confort" 2 "Mode EPS 3 Normal and Sport" 3 "Mode EPS 4" 4 "Mode EPS 5 Casual and Normal" 5 "Mode EPS 6 Casual and Confort" 6 "Mode EPS 7 Casual and Sport" 7 "Mode EPS 8" 8 "Mode EPS 9 Quick and Normal" 9 "Mode EPS 10 Quick and Confort" 10 "Mode EPS 11 Quick and Sport" 11 "Mode EPS 12" 12 "Mode EPS 13" 13 "Drive Mode" 14 "Not used" 15 "Not used";
VAL_ 1297 R_ANC_ModeStatus_MM 0 "No Display" 1 "Mode1_Current seat mode all" 2 "Mode2_Current seat mode front" 3 "Mode3_Current seat mode rear" 4 "Mode4_Current seat mode front Left" 5 "Mode5_Current seat mode front Right" 6 "Not Used" 7 "Unavailable";
VAL_ 1297 CurrentUserState_v2_MM 0 "Guest" 1 "User1" 2 "User2" 3 "User3" 4 "User4" 5 "User5" 6 "Not used" 7 "Not used";
VAL_ 1297 AWDSettingState_MM 0 "Mode 1" 1 "Mode 2" 2 "Mode 3" 3 "Mode 4" 4 "Mode 5" 5 "Mode 6" 6 "Not used" 7 "Not used";
VAL_ 1297 UserSettingCopySource_MM 0 "Not copy" 1 "Guest" 2 "User1" 3 "User2" 4 "User3" 5 "User4" 6 "User5" 7 "Not used";
VAL_ 1297 SuspensionSettingState_MM 0 "Mode VADA 1 (Normal)" 1 "Mode VADA 2 (Comfort)" 2 "Mode VADA 3 (Sport)" 3 "Mode VADA 4" 4 "Mode VADA 5" 5 "Mode VADA 6 (Race)" 6 "Not used" 7 "Not used";
VAL_ 1297 RRsunshadeRequest_MM 0 "No Request" 1 "Open" 2 "Close" 3 "Not used";
VAL_ 1297 R_ANC_ActivationStatus_MM 0 "No Display" 1 "R-ANC status activation" 2 "R-ANC status deactivation" 3 "Unavailable";
VAL_ 1297 ClimHeatedSteeringWheelDisp_MM 0 "No display" 1 "Heated Steering Wheel ON" 2 "Heated Steering Wheel OFF" 3 "Not used";
VAL_ 1297 UserSettingCopyTarget_MM 0 "Not copy" 1 "Guest" 2 "User1" 3 "User2" 4 "User3" 5 "User4" 6 "User5" 7 "Not used";
VAL_ 1297 User3_RegistrationState_MM 0 "Not Registered" 1 "Registered";
VAL_ 1297 User2_RegistrationState_MM 0 "Not Registered" 1 "Registered";
VAL_ 1297 User1_RegistrationState_MM 0 "Not Registered" 1 "Registered";
VAL_ 1297 RRRightMassageActivationState_MM 0 "Massage OFF" 1 "Massage ON";
VAL_ 1297 RRLeftMassageActivationState_MM 0 "Massage OFF" 1 "Massage ON";
VAL_ 1297 RearRightAutoReturnState_MM 0 "AutoReturn OFF" 1 "AutoReturn ON";
VAL_ 1297 RearLeftAutoReturnState_MM 0 "AutoReturn OFF" 1 "AutoReturn ON";
VAL_ 1297 ClimHeatedStrgWheelAutoDisp_MM 0 "No display" 1 "Heated steering wheel Auto ON" 2 "Heated steering wheel Auto OFF" 3 "Not used";
VAL_ 1297 ClimLinkPrioritFRSeatAutoDisp_MM 0 "No display" 1 "Level 1" 2 "Level 2" 3 "Level 3" 4 "Level 4" 5 "Level 5" 6 "OFF" 7 "Not used";
VAL_ 1297 UserSettingCopyRequest_MM 0 "No request" 1 "Request";
VAL_ 1297 User5_RegistrationState_MM 0 "Not Registered" 1 "Registered";
VAL_ 1297 User4_RegistrationState_MM 0 "Not Registered" 1 "Registered";
VAL_ 1297 ClimRightBlowingLevelDisplay_MM 0 "No display" 1 "Level 1" 2 "Level 2" 3 "Level 3" 4 "Level 4" 5 "Level 5" 6 "Level 6" 7 "Level 7" 8 "Level 8" 9 "Level 9" 10 "Level 10" 11 "Level 11" 12 "Level 12" 13 "Level 13" 14 "Level 14" 15 "Blower OFF";
VAL_ 1297 ClimLinkPrioritRRSeatAutoDisp_MM 0 "No display" 1 "Level 1" 2 "Level 2" 3 "Level 3" 4 "Level 4" 5 "Level 5" 6 "OFF" 7 "Not used";
VAL_ 1304 MultimediaCutOffDisplay 0 "No display" 1 "MM cut off warning";
VAL_ 1304 AudioVolumeDisplayAuthorization 0 "No display" 1 "Volume display";
VAL_ 1304 IRStateDisplay_MM 0 "No Display" 1 "IR ON" 2 "IR OFF" 3 "Not Used";
VAL_ 1304 PhoneConnectionDisplayStatus 0 "No display" 1 "Activation request" 2 "Scan" 3 "Wait" 4 "No bluetooth device" 5 "Ready to pair" 6 "Validation request" 7 "Maximum device number" 8 "Delete device request" 9 "Pairing in progress" 10 "Device connected" 11 "Accept PhoneBook" 12 "Pairing failure" 13 "Connection in progress" 14 "Device deleted" 15 "Not used";
VAL_ 1304 HDC_StatusDisplay_MM 0 "HDC Not activated" 1 "HDC Activated" 2 "HDC in Control" 3 "HDC Failure";
VAL_ 1309 ClimFPrearRightBlowRequest_RCP 0 "No Request" 1 "Level 1" 2 "Level 2" 3 "Level 3" 4 "Level 4" 5 "Level 5" 6 "Level 6" 7 "Level 7" 8 "Level 8" 9 "Level 9" 10 "Level 10" 11 "Level 11" 12 "Level 12" 13 "Level 13" 14 "Level 14" 15 "Blower OFF";
VAL_ 1309 ClimFPRearLeftBlowingRequest_RCP 0 "No Request" 1 "Level 1" 2 "Level 2" 3 "Level 3" 4 "Level 4" 5 "Level 5" 6 "Level 6" 7 "Level 7" 8 "Level 8" 9 "Level 9" 10 "Level 10" 11 "Level 11" 12 "Level 12" 13 "Level 13" 14 "Level 14" 15 "Blower OFF";
VAL_ 1309 SecondRowRightSeatAutoReq_RCP 0 "No request" 1 "Auto mode activation" 2 "Auto mode deactivation" 3 "Reset request";
VAL_ 1309 SecondRowLeftSeatRequest_RCP 0 "No request" 1 "OFF request" 2 "Heater Low request" 3 "Heater Middle request" 4 "Heater High request" 5 "Ventilated Low request" 6 "Ventilated Middle request" 7 "Ventilated High request" 8 "Reset request" 9 "Not Used" 10 "Not Used" 11 "Not Used" 12 "Not Used" 13 "Not Used" 14 "Not Used" 15 "Not Used";
VAL_ 1309 SecondRowLeftSeatAutoRequest_RCP 0 "No request" 1 "Auto mode activation" 2 "Auto mode deactivation" 3 "Reset request";
VAL_ 1309 RRsunshade_Movement 0 "Unavailable" 1 "Stopped" 2 "Opening" 3 "Closing" 4 "Anti pinch" 5 "Not used" 6 "Not used" 7 "Not used";
VAL_ 1309 SecondRowRightSeatRequest_RCP 0 "No request" 1 "OFF request" 2 "Heater Low request" 3 "Heater Middle request" 4 "Heater High request" 5 "Ventilated Low request" 6 "Ventilated Middle request" 7 "Ventilated High request" 8 "Reset request" 9 "Not Used" 10 "Not Used" 11 "Not Used" 12 "Not Used" 13 "Not Used" 14 "Not Used" 15 "Not Used";
VAL_ 1309 ThirdRowLeftSeatRequest_RCP 0 "No request" 1 "OFF request" 2 "Heater Low request" 3 "Heater Middle request" 4 "Heater High request" 5 "Reset request" 6 "Not Used" 7 "Not Used";
VAL_ 1309 RRsunshade_Position 0 "Unavailable" 1 "Opened" 2 "Closed" 3 "Not used";
VAL_ 1309 ThirdRowRightSeatAutoRequest_RCP 0 "No Request" 1 "OFF" 2 "ON" 3 "Not Used";
VAL_ 1309 ThirdRowLeftSeatAutoRequest_RCP 0 "No Request" 1 "OFF" 2 "ON" 3 "Not Used";
VAL_ 1309 ThirdRowRightSeatRequest_RCP 0 "No request" 1 "OFF request" 2 "Heater Low request" 3 "Heater Middle request" 4 "Heater High request" 5 "Reset request" 6 "Not Used" 7 "Not Used";
VAL_ 1329 ClimRearLockRequest_FCP 0 "No request" 1 "Rear climate lock request" 2 "Rear climate unlock request" 3 "Reset request";
VAL_ 1329 SecondRowRightSeatAutoReq_FCP 0 "No request" 1 "Auto mode activation" 2 "Auto mode deactivation" 3 "Reset request";
VAL_ 1368 DayNightStatus_MM 0 "day" 1 "night" 2 "Twilight" 3 "Invalid Value";
VAL_ 1375 ClimFPrearRightBlowRequest_FCP 0 "No Request" 1 "Level 1" 2 "Level 2" 3 "Level 3" 4 "Level 4" 5 "Level 5" 6 "Level 6" 7 "Level 7" 8 "Level 8" 9 "Level 9" 10 "Level 10" 11 "Level 11" 12 "Level 12" 13 "Level 13" 14 "Level 14" 15 "Blower OFF";
VAL_ 1375 ClimFPRearLeftBlowingRequest_FCP 0 "No Request" 1 "Level 1" 2 "Level 2" 3 "Level 3" 4 "Level 4" 5 "Level 5" 6 "Level 6" 7 "Level 7" 8 "Level 8" 9 "Level 9" 10 "Level 10" 11 "Level 11" 12 "Level 12" 13 "Level 13" 14 "Level 14" 15 "Blower OFF";
VAL_ 1400 GADE_MM_v2 0 "Sleep or Crank fault, Disable DiagMuxDTC" 1 "AutoACC fault, Disable DiagMuxDTC" 2 "ALL fault, Disable DiagMuxDTC" 3 "ALL fault, Enable DiagMuxDTC" 4 "FOTA switch fault, Disable DiagMuxDTC" 5 "Not used" 6 "Not used" 7 "Unavailable";
VAL_ 1415 DisplayActivation 0 "No display" 1 "Display";
VAL_ 1423 MM_WakeUpSleepCommand 0 "Go to Sleep" 1 "reserved" 2 "reserved" 3 "WakeUp";
VAL_ 1433 Current_Alert_ID_displayed 0 "Table Value430654";
VAL_ 1438 APA_SwitchRequest_MM 0 "Switch released" 1 "Switch pushed";
VAL_ 1445 Uniform_Symbol_003_displayed 0 "No Display" 1 "ActivateState1" 2 "ActivateState2" 3 "ActivateState3";
VAL_ 1445 Uniform_Symbol_002_displayed 0 "No Display" 1 "ActivateState1" 2 "ActivateState2" 3 "ActivateState3";
VAL_ 1445 Uniform_Symbol_001_displayed 0 "No Display" 1 "ActivateState1" 2 "ActivateState2" 3 "ActivateState3";
VAL_ 1445 Uniform_Symbol_000_displayed 0 "No Display" 1 "ActivateState1" 2 "ActivateState2" 3 "ActivateState3";
VAL_ 1445 Uniform_Symbol_007_displayed 0 "No Display" 1 "ActivateState1" 2 "ActivateState2" 3 "ActivateState3";
VAL_ 1445 Uniform_Symbol_006_displayed 0 "No Display" 1 "ActivateState1" 2 "ActivateState2" 3 "ActivateState3";
VAL_ 1445 Uniform_Symbol_005_displayed 0 "No Display" 1 "ActivateState1" 2 "ActivateState2" 3 "ActivateState3";
VAL_ 1445 Uniform_Symbol_004_displayed 0 "No Display" 1 "ActivateState1" 2 "ActivateState2" 3 "ActivateState3";
VAL_ 1445 Uniform_Symbol_011_displayed 0 "No Display" 1 "ActivateState1" 2 "ActivateState2" 3 "ActivateState3";
VAL_ 1445 Uniform_Symbol_010_displayed 0 "No Display" 1 "ActivateState1" 2 "ActivateState2" 3 "ActivateState3";
VAL_ 1445 Uniform_Symbol_009_displayed 0 "No Display" 1 "ActivateState1" 2 "ActivateState2" 3 "ActivateState3";
VAL_ 1445 Uniform_Symbol_008_displayed 0 "No Display" 1 "ActivateState1" 2 "ActivateState2" 3 "ActivateState3";
VAL_ 1445 Uniform_Symbol_015_displayed 0 "No Display" 1 "ActivateState1" 2 "ActivateState2" 3 "ActivateState3";
VAL_ 1445 Uniform_Symbol_014_displayed 0 "No Display" 1 "ActivateState1" 2 "ActivateState2" 3 "ActivateState3";
VAL_ 1445 Uniform_Symbol_013_displayed 0 "No Display" 1 "ActivateState1" 2 "ActivateState2" 3 "ActivateState3";
VAL_ 1445 Uniform_Symbol_012_displayed 0 "No Display" 1 "ActivateState1" 2 "ActivateState2" 3 "ActivateState3";
VAL_ 1445 Uniform_Symbol_019_displayed 0 "No Display" 1 "ActivateState1" 2 "ActivateState2" 3 "ActivateState3";
VAL_ 1445 Uniform_Symbol_018_displayed 0 "No Display" 1 "ActivateState1" 2 "ActivateState2" 3 "ActivateState3";
VAL_ 1445 Uniform_Symbol_017_displayed 0 "No Display" 1 "ActivateState1" 2 "ActivateState2" 3 "ActivateState3";
VAL_ 1445 Uniform_Symbol_016_displayed 0 "No Display" 1 "ActivateState1" 2 "ActivateState2" 3 "ActivateState3";
VAL_ 1445 Uniform_Symbol_023_displayed 0 "No Display" 1 "ActivateState1" 2 "ActivateState2" 3 "ActivateState3";
VAL_ 1445 Uniform_Symbol_022_displayed 0 "No Display" 1 "ActivateState1" 2 "ActivateState2" 3 "ActivateState3";
VAL_ 1445 Uniform_Symbol_021_displayed 0 "No Display" 1 "ActivateState1" 2 "ActivateState2" 3 "ActivateState3";
VAL_ 1445 Uniform_Symbol_020_displayed 0 "No Display" 1 "ActivateState1" 2 "ActivateState2" 3 "ActivateState3";
VAL_ 1445 Uniform_Symbol_027_displayed 0 "No Display" 1 "ActivateState1" 2 "ActivateState2" 3 "ActivateState3";
VAL_ 1445 Uniform_Symbol_026_displayed 0 "No Display" 1 "ActivateState1" 2 "ActivateState2" 3 "ActivateState3";
VAL_ 1445 Uniform_Symbol_025_displayed 0 "No Display" 1 "ActivateState1" 2 "ActivateState2" 3 "ActivateState3";
VAL_ 1445 Uniform_Symbol_024_displayed 0 "No Display" 1 "ActivateState1" 2 "ActivateState2" 3 "ActivateState3";
VAL_ 1445 Uniform_Symbol_031_displayed 0 "No Display" 1 "ActivateState1" 2 "ActivateState2" 3 "ActivateState3";
VAL_ 1445 Uniform_Symbol_030_displayed 0 "No Display" 1 "ActivateState1" 2 "ActivateState2" 3 "ActivateState3";
VAL_ 1445 Uniform_Symbol_029_displayed 0 "No Display" 1 "ActivateState1" 2 "ActivateState2" 3 "ActivateState3";
VAL_ 1445 Uniform_Symbol_028_displayed 0 "No Display" 1 "ActivateState1" 2 "ActivateState2" 3 "ActivateState3";
VAL_ 1512 CP_DisplayFailure 0 "no default" 1 "display default";
VAL_ 1515 Uniform_Symbol_067_displayed 0 "No Display" 1 "ActivateState1" 2 "ActivateState2" 3 "ActivateState3";
VAL_ 1515 Uniform_Symbol_066_displayed 0 "No Display" 1 "ActivateState1" 2 "ActivateState2" 3 "ActivateState3";
VAL_ 1515 Uniform_Symbol_065_displayed 0 "No Display" 1 "ActivateState1" 2 "ActivateState2" 3 "ActivateState3";
VAL_ 1515 Uniform_Symbol_064_displayed 0 "No Display" 1 "ActivateState1" 2 "ActivateState2" 3 "ActivateState3";
VAL_ 1515 Uniform_Symbol_071_displayed 0 "No Display" 1 "ActivateState1" 2 "ActivateState2" 3 "ActivateState3";
VAL_ 1515 Uniform_Symbol_070_displayed 0 "No Display" 1 "ActivateState1" 2 "ActivateState2" 3 "ActivateState3";
VAL_ 1515 Uniform_Symbol_069_displayed 0 "No Display" 1 "ActivateState1" 2 "ActivateState2" 3 "ActivateState3";
VAL_ 1515 Uniform_Symbol_068_displayed 0 "No Display" 1 "ActivateState1" 2 "ActivateState2" 3 "ActivateState3";
VAL_ 1515 Uniform_Symbol_075_displayed 0 "No Display" 1 "ActivateState1" 2 "ActivateState2" 3 "ActivateState3";
VAL_ 1515 Uniform_Symbol_074_displayed 0 "No Display" 1 "ActivateState1" 2 "ActivateState2" 3 "ActivateState3";
VAL_ 1515 Uniform_Symbol_073_displayed 0 "No Display" 1 "ActivateState1" 2 "ActivateState2" 3 "ActivateState3";
VAL_ 1515 Uniform_Symbol_072_displayed 0 "No Display" 1 "ActivateState1" 2 "ActivateState2" 3 "ActivateState3";
VAL_ 1515 Uniform_Symbol_079_displayed 0 "No Display" 1 "ActivateState1" 2 "ActivateState2" 3 "ActivateState3";
VAL_ 1515 Uniform_Symbol_078_displayed 0 "No Display" 1 "ActivateState1" 2 "ActivateState2" 3 "ActivateState3";
VAL_ 1515 Uniform_Symbol_077_displayed 0 "No Display" 1 "ActivateState1" 2 "ActivateState2" 3 "ActivateState3";
VAL_ 1515 Uniform_Symbol_076_displayed 0 "No Display" 1 "ActivateState1" 2 "ActivateState2" 3 "ActivateState3";
VAL_ 1515 Uniform_Symbol_083_displayed 0 "No Display" 1 "ActivateState1" 2 "ActivateState2" 3 "ActivateState3";
VAL_ 1515 Uniform_Symbol_082_displayed 0 "No Display" 1 "ActivateState1" 2 "ActivateState2" 3 "ActivateState3";
VAL_ 1515 Uniform_Symbol_081_displayed 0 "No Display" 1 "ActivateState1" 2 "ActivateState2" 3 "ActivateState3";
VAL_ 1515 Uniform_Symbol_080_displayed 0 "No Display" 1 "ActivateState1" 2 "ActivateState2" 3 "ActivateState3";
VAL_ 1515 Uniform_Symbol_087_displayed 0 "No Display" 1 "ActivateState1" 2 "ActivateState2" 3 "ActivateState3";
VAL_ 1515 Uniform_Symbol_086_displayed 0 "No Display" 1 "ActivateState1" 2 "ActivateState2" 3 "ActivateState3";
VAL_ 1515 Uniform_Symbol_085_displayed 0 "No Display" 1 "ActivateState1" 2 "ActivateState2" 3 "ActivateState3";
VAL_ 1515 Uniform_Symbol_084_displayed 0 "No Display" 1 "ActivateState1" 2 "ActivateState2" 3 "ActivateState3";
VAL_ 1515 Uniform_Symbol_091_displayed 0 "No Display" 1 "ActivateState1" 2 "ActivateState2" 3 "ActivateState3";
VAL_ 1515 Uniform_Symbol_090_displayed 0 "No Display" 1 "ActivateState1" 2 "ActivateState2" 3 "ActivateState3";
VAL_ 1515 Uniform_Symbol_089_displayed 0 "No Display" 1 "ActivateState1" 2 "ActivateState2" 3 "ActivateState3";
VAL_ 1515 Uniform_Symbol_088_displayed 0 "No Display" 1 "ActivateState1" 2 "ActivateState2" 3 "ActivateState3";
VAL_ 1515 Uniform_Symbol_095_displayed 0 "No Display" 1 "ActivateState1" 2 "ActivateState2" 3 "ActivateState3";
VAL_ 1515 Uniform_Symbol_094_displayed 0 "No Display" 1 "ActivateState1" 2 "ActivateState2" 3 "ActivateState3";
VAL_ 1515 Uniform_Symbol_093_displayed 0 "No Display" 1 "ActivateState1" 2 "ActivateState2" 3 "ActivateState3";
VAL_ 1515 Uniform_Symbol_092_displayed 0 "No Display" 1 "ActivateState1" 2 "ActivateState2" 3 "ActivateState3";
VAL_ 1519 KeyLinkInitializationState 0 "Initialization in progress" 1 "Initialization completed";
VAL_ 1519 KeyLinkActivationState 0 "Activate" 1 "Deactivate";
VAL_ 1525 Uniform_Symbol_035_displayed 0 "No Display" 1 "ActivateState1" 2 "ActivateState2" 3 "ActivateState3";
VAL_ 1525 Uniform_Symbol_034_displayed 0 "No Display" 1 "ActivateState1" 2 "ActivateState2" 3 "ActivateState3";
VAL_ 1525 Uniform_Symbol_033_displayed 0 "No Display" 1 "ActivateState1" 2 "ActivateState2" 3 "ActivateState3";
VAL_ 1525 Uniform_Symbol_032_displayed 0 "No Display" 1 "ActivateState1" 2 "ActivateState2" 3 "ActivateState3";
VAL_ 1525 Uniform_Symbol_039_displayed 0 "No Display" 1 "ActivateState1" 2 "ActivateState2" 3 "ActivateState3";
VAL_ 1525 Uniform_Symbol_038_displayed 0 "No Display" 1 "ActivateState1" 2 "ActivateState2" 3 "ActivateState3";
VAL_ 1525 Uniform_Symbol_037_displayed 0 "No Display" 1 "ActivateState1" 2 "ActivateState2" 3 "ActivateState3";
VAL_ 1525 Uniform_Symbol_036_displayed 0 "No Display" 1 "ActivateState1" 2 "ActivateState2" 3 "ActivateState3";
VAL_ 1525 Uniform_Symbol_043_displayed 0 "No Display" 1 "ActivateState1" 2 "ActivateState2" 3 "ActivateState3";
VAL_ 1525 Uniform_Symbol_042_displayed 0 "No Display" 1 "ActivateState1" 2 "ActivateState2" 3 "ActivateState3";
VAL_ 1525 Uniform_Symbol_041_displayed 0 "No Display" 1 "ActivateState1" 2 "ActivateState2" 3 "ActivateState3";
VAL_ 1525 Uniform_Symbol_040_displayed 0 "No Display" 1 "ActivateState1" 2 "ActivateState2" 3 "ActivateState3";
VAL_ 1525 Uniform_Symbol_047_displayed 0 "No Display" 1 "ActivateState1" 2 "ActivateState2" 3 "ActivateState3";
VAL_ 1525 Uniform_Symbol_046_displayed 0 "No Display" 1 "ActivateState1" 2 "ActivateState2" 3 "ActivateState3";
VAL_ 1525 Uniform_Symbol_045_displayed 0 "No Display" 1 "ActivateState1" 2 "ActivateState2" 3 "ActivateState3";
VAL_ 1525 Uniform_Symbol_044_displayed 0 "No Display" 1 "ActivateState1" 2 "ActivateState2" 3 "ActivateState3";
VAL_ 1525 Uniform_Symbol_051_displayed 0 "No Display" 1 "ActivateState1" 2 "ActivateState2" 3 "ActivateState3";
VAL_ 1525 Uniform_Symbol_050_displayed 0 "No Display" 1 "ActivateState1" 2 "ActivateState2" 3 "ActivateState3";
VAL_ 1525 Uniform_Symbol_049_displayed 0 "No Display" 1 "ActivateState1" 2 "ActivateState2" 3 "ActivateState3";
VAL_ 1525 Uniform_Symbol_048_displayed 0 "No Display" 1 "ActivateState1" 2 "ActivateState2" 3 "ActivateState3";
VAL_ 1525 Uniform_Symbol_055_displayed 0 "No Display" 1 "ActivateState1" 2 "ActivateState2" 3 "ActivateState3";
VAL_ 1525 Uniform_Symbol_054_displayed 0 "No Display" 1 "ActivateState1" 2 "ActivateState2" 3 "ActivateState3";
VAL_ 1525 Uniform_Symbol_053_displayed 0 "No Display" 1 "ActivateState1" 2 "ActivateState2" 3 "ActivateState3";
VAL_ 1525 Uniform_Symbol_052_displayed 0 "No Display" 1 "ActivateState1" 2 "ActivateState2" 3 "ActivateState3";
VAL_ 1525 Uniform_Symbol_059_displayed 0 "No Display" 1 "ActivateState1" 2 "ActivateState2" 3 "ActivateState3";
VAL_ 1525 Uniform_Symbol_058_displayed 0 "No Display" 1 "ActivateState1" 2 "ActivateState2" 3 "ActivateState3";
VAL_ 1525 Uniform_Symbol_057_displayed 0 "No Display" 1 "ActivateState1" 2 "ActivateState2" 3 "ActivateState3";
VAL_ 1525 Uniform_Symbol_056_displayed 0 "No Display" 1 "ActivateState1" 2 "ActivateState2" 3 "ActivateState3";
VAL_ 1525 Uniform_Symbol_063_displayed 0 "No Display" 1 "ActivateState1" 2 "ActivateState2" 3 "ActivateState3";
VAL_ 1525 Uniform_Symbol_062_displayed 0 "No Display" 1 "ActivateState1" 2 "ActivateState2" 3 "ActivateState3";
VAL_ 1525 Uniform_Symbol_061_displayed 0 "No Display" 1 "ActivateState1" 2 "ActivateState2" 3 "ActivateState3";
VAL_ 1525 Uniform_Symbol_060_displayed 0 "No Display" 1 "ActivateState1" 2 "ActivateState2" 3 "ActivateState3";
VAL_ 1542 RADIO_to_AMPLI 0 "Table Value430576";
VAL_ 1576 RADIO_to_CLUSTER 0 "Table Value161226";
VAL_ 1617 RADIO_to_METER2 0 "Table Value161227";
VAL_ 1661 VDCDeactivationDisplayRequest_MM 0 "No request" 1 "VDC deactivated display request";
VAL_ 1670 AMPLI_to_RADIO 0 "Table Value430575";
VAL_ 1704 CLUSTER_to_RADIO 0 "Table Value161222";
VAL_ 1745 METER2_to_RADIO 0 "Table Value161224";
VAL_ 2609102854 IVI_WakeUp_Signal 0 "Table Value16486";
